[part 1 of 2: packages /AUTOSAR_Platform/DataConstrs to /PATAC/MSM/DataTypes/ImplementationDataTypes]
AUTOSAR XML (schema 4-0-3)
standard types defined: Boolean, UInt16, UInt32, UInt8
package /AUTOSAR_Platform/DataConstrs
  range DC_Boolean: raw 0..1
  range DC_UInt16: raw 0..65535
  range DC_UInt8: raw 0..255
package /PATAC/Facility/DataTypes/Implementation
  unit NoUnit: factor-si-to-unit=1, offset-si-to-unit=0
package /PATAC/MSM/ComponentTypes
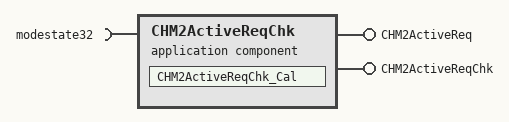
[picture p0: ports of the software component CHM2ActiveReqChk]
  application sw component type CHM2ActiveReqChk
    provide port CHM2ActiveReq: nonqueued-sender-com-spec{data-element=CHM2ActiveReq/Val, init-value=0}, provided-interface=CHM2ActiveReq
    provide port CHM2ActiveReqChk: server-com-spec{operation=CHM2ActiveReqChk/Cal, queue-length=1}, provided-interface=CHM2ActiveReqChk
    require port modestate32: nonqueued-receiver-com-spec{data-element=modestate32/Val, filter=data-filter-type=ALWAYS, init-value=0}, required-interface=modestate32
    behavior CHM2ActiveReqChk_InternalBehavior
      operation invoked event OIT_CHM2ActiveReqChk_Cal_CHM2ActiveReqChk_Cal: start-on-event=CHM2ActiveReqChk_Cal, operation=CHM2ActiveReqChk.Cal
      runnable CHM2ActiveReqChk_Cal
        data-receive-point-by-arguments:
          access REC_modestate32_Val: accessed-variable=modestate32.Val
        data-send-points:
          access SEND_CHM2ActiveReq_Val: accessed-variable=CHM2ActiveReq.Val
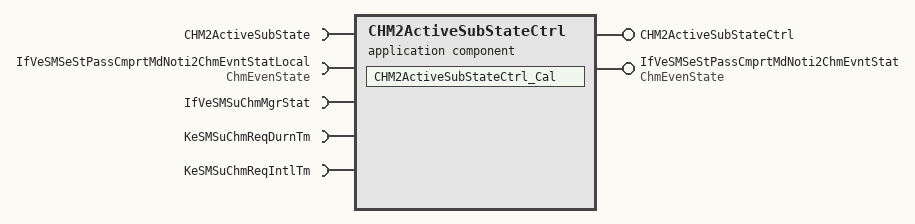
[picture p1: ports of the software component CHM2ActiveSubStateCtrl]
  application sw component type CHM2ActiveSubStateCtrl
    provide port CHM2ActiveSubStateCtrl: server-com-spec{operation=CHM2ActiveSubStateCtrl/Cal, queue-length=1}, provided-interface=CHM2ActiveSubStateCtrl
    provide port IfVeSMSeStPassCmprtMdNoti2ChmEvntStat: nonqueued-sender-com-spec{data-element=ChmEvenState/Val, init-value=0}, provided-interface=ChmEvenState
    5 x require port:
      CHM2ActiveSubState: nonqueued-receiver-com-spec{data-element=CHM2ActiveSubState/Val, filter=data-filter-type=ALWAYS, init-value=0}, required-interface=CHM2ActiveSubState
      IfVeSMSeStPassCmprtMdNoti2ChmEvntStatLocal: nonqueued-receiver-com-spec{data-element=ChmEvenState/Val, filter=data-filter-type=ALWAYS, init-value=0}, required-interface=ChmEvenState
      IfVeSMSuChmMgrStat: nonqueued-receiver-com-spec{data-element=IfVeSMSuChmMgrStat/Val, filter=data-filter-type=ALWAYS, init-value=0}, required-interface=IfVeSMSuChmMgrStat
      KeSMSuChmReqDurnTm: parameter-require-com-spec{init-value=200, parameter=KeSMSuChmReqDurnTm/Val}, required-interface=KeSMSuChmReqDurnTm
      KeSMSuChmReqIntlTm: parameter-require-com-spec{init-value=50, parameter=KeSMSuChmReqIntlTm/Val}, required-interface=KeSMSuChmReqIntlTm
    behavior CHM2ActiveSubStateCtrl_InternalBehavior
      operation invoked event OIT_CHM2ActiveSubStateCtrl_Cal_CHM2ActiveSubStateCtrl_Cal: start-on-event=CHM2ActiveSubStateCtrl_Cal, operation=CHM2ActiveSubStateCtrl.Cal
      runnable CHM2ActiveSubStateCtrl_Cal
        data-receive-point-by-arguments:
          access REC_CHM2ActiveSubState_Val: accessed-variable=CHM2ActiveSubState.Val
          access REC_IfVeSMSeStPassCmprtMdNoti2ChmEvntStatLocal_Val: accessed-variable=IfVeSMSeStPassCmprtMdNoti2ChmEvntStatLocal.Val
          access REC_IfVeSMSuChmMgrStat_Val: accessed-variable=IfVeSMSuChmMgrStat.Val
        data-send-points:
          access SEND_IfVeSMSeStPassCmprtMdNoti2ChmEvntStat_Val: accessed-variable=IfVeSMSeStPassCmprtMdNoti2ChmEvntStat.Val
        parameter access PA_KeSMSuChmReqDurnTm_Val: accessed-parameter=KeSMSuChmReqDurnTm.Val
        parameter access PA_KeSMSuChmReqIntlTm_Val: accessed-parameter=KeSMSuChmReqIntlTm.Val
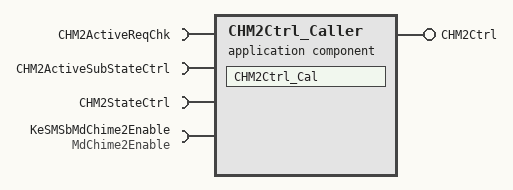
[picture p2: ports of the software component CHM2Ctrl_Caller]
  application sw component type CHM2Ctrl_Caller
    provide port CHM2Ctrl: server-com-spec{operation=CHM2Ctrl/Cal, queue-length=1}, provided-interface=CHM2Ctrl
    4 x require port:
      CHM2ActiveReqChk: client-com-spec=CHM2ActiveReqChk/Cal, required-interface=CHM2ActiveReqChk
      CHM2ActiveSubStateCtrl: client-com-spec=CHM2ActiveSubStateCtrl/Cal, required-interface=CHM2ActiveSubStateCtrl
      CHM2StateCtrl: client-com-spec=CHM2StateCtrl/Cal, required-interface=CHM2StateCtrl
      KeSMSbMdChime2Enable: parameter-require-com-spec{init-value=0, parameter=MdChime2Enable/Val}, required-interface=MdChime2Enable
    behavior CHM2Ctrl_Caller_InternalBehavior
      operation invoked event OIT_CHM2Ctrl_Cal_CHM2Ctrl_Cal: start-on-event=CHM2Ctrl_Cal, operation=CHM2Ctrl.Cal
      runnable CHM2Ctrl_Cal
        parameter access PA_KeSMSbMdChime2Enable_Val: accessed-parameter=KeSMSbMdChime2Enable.Val
        sync call SC_CHM2ActiveReqChk_Cal: operation=CHM2ActiveReqChk.Cal, timeout=0
        sync call SC_CHM2ActiveSubStateCtrl_Cal: operation=CHM2ActiveSubStateCtrl.Cal, timeout=0
        sync call SC_CHM2StateCtrl_Cal: operation=CHM2StateCtrl.Cal, timeout=0
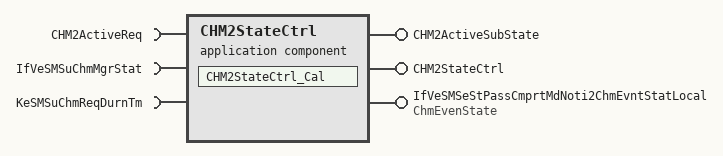
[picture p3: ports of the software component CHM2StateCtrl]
  application sw component type CHM2StateCtrl
    provide port CHM2ActiveSubState: nonqueued-sender-com-spec{data-element=CHM2ActiveSubState/Val, init-value=0}, provided-interface=CHM2ActiveSubState
    provide port CHM2StateCtrl: server-com-spec{operation=CHM2StateCtrl/Cal, queue-length=1}, provided-interface=CHM2StateCtrl
    provide port IfVeSMSeStPassCmprtMdNoti2ChmEvntStatLocal: nonqueued-sender-com-spec{data-element=ChmEvenState/Val, init-value=0}, provided-interface=ChmEvenState
    require port CHM2ActiveReq: nonqueued-receiver-com-spec{data-element=CHM2ActiveReq/Val, filter=data-filter-type=ALWAYS, init-value=0}, required-interface=CHM2ActiveReq
    require port IfVeSMSuChmMgrStat: nonqueued-receiver-com-spec{data-element=IfVeSMSuChmMgrStat/Val, filter=data-filter-type=ALWAYS, init-value=0}, required-interface=IfVeSMSuChmMgrStat
    require port KeSMSuChmReqDurnTm: parameter-require-com-spec{init-value=200, parameter=KeSMSuChmReqDurnTm/Val}, required-interface=KeSMSuChmReqDurnTm
    behavior CHM2StateCtrl_InternalBehavior
      operation invoked event OIT_CHM2StateCtrl_Cal_CHM2StateCtrl_Cal: start-on-event=CHM2StateCtrl_Cal, operation=CHM2StateCtrl.Cal
      runnable CHM2StateCtrl_Cal
        data-receive-point-by-arguments:
          access REC_CHM2ActiveReq_Val: accessed-variable=CHM2ActiveReq.Val
          access REC_IfVeSMSuChmMgrStat_Val: accessed-variable=IfVeSMSuChmMgrStat.Val
        data-send-points:
          access SEND_CHM2ActiveSubState_Val: accessed-variable=CHM2ActiveSubState.Val
          access SEND_IfVeSMSeStPassCmprtMdNoti2ChmEvntStatLocal_Val: accessed-variable=IfVeSMSeStPassCmprtMdNoti2ChmEvntStatLocal.Val
        parameter access PA_KeSMSuChmReqDurnTm_Val: accessed-parameter=KeSMSuChmReqDurnTm.Val
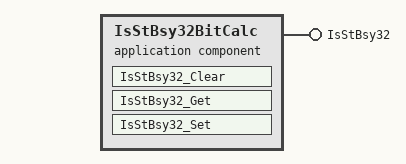
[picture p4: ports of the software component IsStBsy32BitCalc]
  application sw component type IsStBsy32BitCalc
    provide port IsStBsy32: provided-interface=IsStBsy32
      provided-com-specs:
        operation=IsStBsy32/Clear, queue-length=1
        operation=IsStBsy32/Get, queue-length=1
        operation=IsStBsy32/Set, queue-length=1
    behavior IsStBsy32BitCalc_InternalBehavior
      operation invoked event OIT_IsStBsy32_Clear_IsStBsy32_Clear: start-on-event=IsStBsy32_Clear, operation=IsStBsy32.Clear
      operation invoked event OIT_IsStBsy32_Get_IsStBsy32_Get: start-on-event=IsStBsy32_Get, operation=IsStBsy32.Get
      operation invoked event OIT_IsStBsy32_Set_IsStBsy32_Set: start-on-event=IsStBsy32_Set, operation=IsStBsy32.Set
      runnable IsStBsy32_Clear
      runnable IsStBsy32_Get
      runnable IsStBsy32_Set
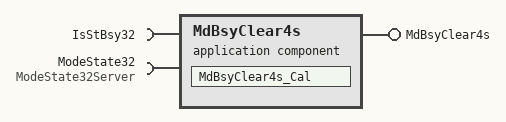
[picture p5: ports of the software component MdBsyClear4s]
  application sw component type MdBsyClear4s
    provide port MdBsyClear4s: server-com-spec{operation=MdBsyClear4s/Cal, queue-length=1}, provided-interface=MdBsyClear4s
    require port IsStBsy32: required-com-specs=[IsStBsy32/Clear, IsStBsy32/Get, IsStBsy32/Set], required-interface=IsStBsy32
    require port ModeState32: required-com-specs=[ModeState32Server/Clear, ModeState32Server/Get, ModeState32Server/Set], required-interface=ModeState32Server
    behavior MdBsyClear4s_InternalBehavior
      operation invoked event OIT_MdBsyClear4s_Cal_MdBsyClear4s_Cal: start-on-event=MdBsyClear4s_Cal, operation=MdBsyClear4s.Cal
      runnable MdBsyClear4s_Cal
        sync call SC_IsStBsy32_Clear: operation=IsStBsy32.Clear, timeout=0
        sync call SC_ModeState32_Get: operation=ModeState32.Get, timeout=0
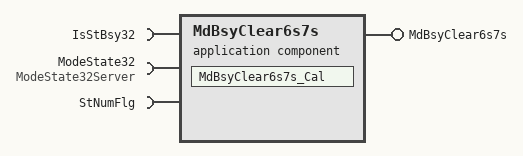
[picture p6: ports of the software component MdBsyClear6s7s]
  application sw component type MdBsyClear6s7s
    provide port MdBsyClear6s7s: server-com-spec{operation=MdBsyClear6s7s/Cal, queue-length=1}, provided-interface=MdBsyClear6s7s
    require port IsStBsy32: required-com-specs=[IsStBsy32/Clear, IsStBsy32/Get, IsStBsy32/Set], required-interface=IsStBsy32
    require port ModeState32: required-com-specs=[ModeState32Server/Clear, ModeState32Server/Get, ModeState32Server/Set], required-interface=ModeState32Server
    require port StNumFlg: required-interface=StNumFlg
      required-com-specs:
        data-element=Is4s, filter=data-filter-type=ALWAYS, init-value=0
        data-element=Is6s, filter=data-filter-type=ALWAYS, init-value=0
        data-element=Is6s7s, filter=data-filter-type=ALWAYS, init-value=0
        data-element=Is7s, filter=data-filter-type=ALWAYS, init-value=0
    behavior MdBsyClear6s7s_InternalBehavior
      operation invoked event OIT_MdBsyClear6s7s_Cal_MdBsyClear6s7s_Cal: start-on-event=MdBsyClear6s7s_Cal, operation=MdBsyClear6s7s.Cal
      runnable MdBsyClear6s7s_Cal
        data-receive-point-by-arguments:
          access REC_StNumFlg_Is6s: accessed-variable=StNumFlg.Is6s
          access REC_StNumFlg_Is7s: accessed-variable=StNumFlg.Is7s
        sync call SC_IsStBsy32_Clear: operation=IsStBsy32.Clear, timeout=0
        sync call SC_ModeState32_Get: operation=ModeState32.Get, timeout=0
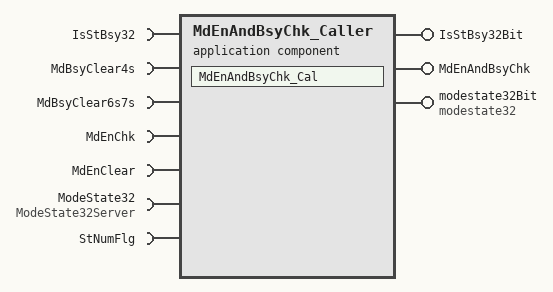
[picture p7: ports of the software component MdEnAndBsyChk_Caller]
  application sw component type MdEnAndBsyChk_Caller
    provide port IsStBsy32Bit: nonqueued-sender-com-spec{data-element=IsStBsy32Bit/Val, init-value=0}, provided-interface=IsStBsy32Bit
    provide port MdEnAndBsyChk: server-com-spec{operation=MdEnAndBsyChk/Cal, queue-length=1}, provided-interface=MdEnAndBsyChk
    provide port modestate32Bit: nonqueued-sender-com-spec{data-element=modestate32/Val, init-value=0}, provided-interface=modestate32
    7 x require port:
      IsStBsy32: required-com-specs=[IsStBsy32/Clear, IsStBsy32/Get, IsStBsy32/Set], required-interface=IsStBsy32
      MdBsyClear4s: client-com-spec=MdBsyClear4s/Cal, required-interface=MdBsyClear4s
      MdBsyClear6s7s: client-com-spec=MdBsyClear6s7s/Cal, required-interface=MdBsyClear6s7s
      MdEnChk: client-com-spec=MdEnChk/Cal, required-interface=MdEnChk
      MdEnClear: client-com-spec=MdEnClear/Cal, required-interface=MdEnClear
      ModeState32: required-com-specs=[ModeState32Server/Clear, ModeState32Server/Get, ModeState32Server/Set], required-interface=ModeState32Server
      StNumFlg: required-interface=StNumFlg
        required-com-specs:
          data-element=Is4s, filter=data-filter-type=ALWAYS, init-value=0
          data-element=Is6s, filter=data-filter-type=ALWAYS, init-value=0
          data-element=Is6s7s, filter=data-filter-type=ALWAYS, init-value=0
          data-element=Is7s, filter=data-filter-type=ALWAYS, init-value=0
    behavior MdEnAndBsyChk_Caller_InternalBehavior
      operation invoked event OIT_MdEnAndBsyChk_Cal_MdEnAndBsyChk_Cal: start-on-event=MdEnAndBsyChk_Cal, operation=MdEnAndBsyChk.Cal
      runnable MdEnAndBsyChk_Cal
        data-receive-point-by-arguments:
          4 x access:
            REC_StNumFlg_Is4s: accessed-variable=StNumFlg.Is4s
            REC_StNumFlg_Is6s: accessed-variable=StNumFlg.Is6s
            REC_StNumFlg_Is6s7s: accessed-variable=StNumFlg.Is6s7s
            REC_StNumFlg_Is7s: accessed-variable=StNumFlg.Is7s
        data-send-points:
          access SEND_IsStBsy32Bit_Val: accessed-variable=IsStBsy32Bit.Val
          access SEND_modestate32_Val: accessed-variable=modestate32Bit.Val
        6 x sync call, all with timeout=0:
          SC_IsStBsy32_Get: operation=IsStBsy32.Get
          SC_MdBsyClear4s_Cal: operation=MdBsyClear4s.Cal
          SC_MdBsyClear6s7s_Cal: operation=MdBsyClear6s7s.Cal
          SC_MdEnChk_Cal: operation=MdEnChk.Cal
          SC_MdEnClear_Cal: operation=MdEnClear.Cal
          SC_ModeState32_Get: operation=ModeState32.Get
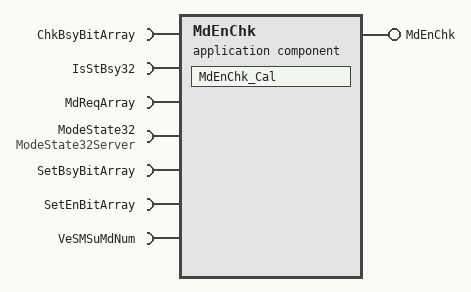
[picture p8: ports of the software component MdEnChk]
  application sw component type MdEnChk
    provide port MdEnChk: server-com-spec{operation=MdEnChk/Cal, queue-length=1}, provided-interface=MdEnChk
    7 x require port:
      ChkBsyBitArray: nonqueued-receiver-com-spec{data-element=ChkBsyBitArray/Val, filter=data-filter-type=ALWAYS, init-value=32 x 0}, required-interface=ChkBsyBitArray
      IsStBsy32: required-com-specs=[IsStBsy32/Clear, IsStBsy32/Get, IsStBsy32/Set], required-interface=IsStBsy32
      MdReqArray: nonqueued-receiver-com-spec{data-element=MdReqArray/Val, filter=data-filter-type=ALWAYS, init-value=32 x 0}, required-interface=MdReqArray
      ModeState32: required-com-specs=[ModeState32Server/Clear, ModeState32Server/Get, ModeState32Server/Set], required-interface=ModeState32Server
      SetBsyBitArray: nonqueued-receiver-com-spec{data-element=SetBsyBitArray/Val, filter=data-filter-type=ALWAYS, init-value=32 x 0}, required-interface=SetBsyBitArray
      SetEnBitArray: nonqueued-receiver-com-spec{data-element=SetEnBitArray/Val, filter=data-filter-type=ALWAYS, init-value=32 x 0}, required-interface=SetEnBitArray
      VeSMSuMdNum: nonqueued-receiver-com-spec{data-element=VeSMSuMdNum/Val, filter=data-filter-type=ALWAYS, init-value=0}, required-interface=VeSMSuMdNum
    behavior MdEnChk_InternalBehavior
      operation invoked event OIT_MdEnChk_Cal_MdEnChk_Cal: start-on-event=MdEnChk_Cal, operation=MdEnChk.Cal
      runnable MdEnChk_Cal
        data-receive-point-by-arguments:
          5 x access:
            REC_ChkBsyBitArray_Val: accessed-variable=ChkBsyBitArray.Val
            REC_MdReqArray_Val: accessed-variable=MdReqArray.Val
            REC_SetBsyBitArray_Val: accessed-variable=SetBsyBitArray.Val
            REC_SetEnBitArray_Val: accessed-variable=SetEnBitArray.Val
            REC_VeSMSuMdNum_Val: accessed-variable=VeSMSuMdNum.Val
        sync call SC_IsStBsy32_Get: operation=IsStBsy32.Get, timeout=0
        sync call SC_IsStBsy32_Set: operation=IsStBsy32.Set, timeout=0
        sync call SC_ModeState32_Set: operation=ModeState32.Set, timeout=0
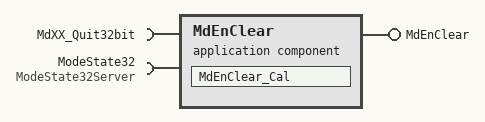
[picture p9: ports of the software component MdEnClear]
  application sw component type MdEnClear
    provide port MdEnClear: server-com-spec{operation=MdEnClear/Cal, queue-length=1}, provided-interface=MdEnClear
    require port MdXX_Quit32bit: nonqueued-receiver-com-spec{data-element=MdXX_Quit32bit/Val, filter=data-filter-type=ALWAYS, init-value=0}, required-interface=MdXX_Quit32bit
    require port ModeState32: required-com-specs=[ModeState32Server/Clear, ModeState32Server/Get, ModeState32Server/Set], required-interface=ModeState32Server
    behavior MdEnClear_InternalBehavior
      operation invoked event OIT_MdEnClear_Cal_MdEnClear_Cal: start-on-event=MdEnClear_Cal, operation=MdEnClear.Cal
      runnable MdEnClear_Cal
        data-receive-point-by-arguments:
          access REC_MdXX_Quit32bit_Val: accessed-variable=MdXX_Quit32bit.Val
        sync call SC_ModeState32_Clear: operation=ModeState32.Clear, timeout=0
        sync call SC_ModeState32_Get: operation=ModeState32.Get, timeout=0
  application sw component type MdSWReqChk
    6 x provide port:
      ChkBsyBitArray: nonqueued-sender-com-spec=data-element=ChkBsyBitArray/Val, provided-interface=ChkBsyBitArray
      MdReqArray: nonqueued-sender-com-spec=data-element=MdReqArray/Val, provided-interface=MdReqArray
      MdSWReqChk: server-com-spec{operation=MdSWReqChk/Cal, queue-length=1}, provided-interface=MdSWReqChk
      SetBsyBitArray: nonqueued-sender-com-spec=data-element=SetBsyBitArray/Val, provided-interface=SetBsyBitArray
      SetEnBitArray: nonqueued-sender-com-spec=data-element=SetEnBitArray/Val, provided-interface=SetEnBitArray
      VeSMSuMdNum: nonqueued-sender-com-spec=data-element=VeSMSuMdNum/Val, provided-interface=VeSMSuMdNum
    45 x require port:
      acsEntyMdReq: nonqueued-receiver-com-spec{data-element=MdReq/Val, filter=data-filter-type=ALWAYS, init-value=0}, required-interface=MdReq
      acsExtMdReq: nonqueued-receiver-com-spec{data-element=MdReq/Val, filter=data-filter-type=ALWAYS, init-value=0}, required-interface=MdReq
      AllLugMdReq: nonqueued-receiver-com-spec{data-element=MdReq/Val, filter=data-filter-type=ALWAYS, init-value=0}, required-interface=MdReq
      AllVipMdReq: nonqueued-receiver-com-spec{data-element=MdReq/Val, filter=data-filter-type=ALWAYS, init-value=0}, required-interface=MdReq
      EZE4sLtMdReq: nonqueued-receiver-com-spec{data-element=AnyModeAjust/Val, filter=data-filter-type=ALWAYS, init-value=0}, required-interface=AnyModeAjust
      EZE4sRtMdReq: nonqueued-receiver-com-spec{data-element=AnyModeAjust/Val, filter=data-filter-type=ALWAYS, init-value=0}, required-interface=AnyModeAjust
      EZQ4sLtMdReq: nonqueued-receiver-com-spec{data-element=AnyModeAjust/Val, filter=data-filter-type=ALWAYS, init-value=0}, required-interface=AnyModeAjust
      EZQ4sRtMdReq: nonqueued-receiver-com-spec{data-element=AnyModeAjust/Val, filter=data-filter-type=ALWAYS, init-value=0}, required-interface=AnyModeAjust
      IfVeSMSuSecRwLtStFrwdBkwdPos: nonqueued-receiver-com-spec{data-element=IfVeSMSuSecRwLtStFrwdBkwdPos/Val, filter=data-filter-type=ALWAYS, init-value=0}, required-interface=IfVeSMSuSecRwLtStFrwdBkwdPos
      IfVeSMSuSecRwRtStFrwdBkwdPos: nonqueued-receiver-com-spec{data-element=PercPos/Val, filter=data-filter-type=ALWAYS, init-value=0}, required-interface=PercPos
      IntimacyRtMdReq: nonqueued-receiver-com-spec{data-element=AnyModeAjust/Val, filter=data-filter-type=ALWAYS, init-value=0}, required-interface=AnyModeAjust
      INTMMdReq: nonqueued-receiver-com-spec{data-element=MdReq/Val, filter=data-filter-type=ALWAYS, init-value=0}, required-interface=MdReq
      KeSMSAutoEZEFwdBkwdPosEna: parameter-require-com-spec{init-value=0, parameter=KeSMSAutoEZEFwdBkwdPosEna/Val}, required-interface=KeSMSAutoEZEFwdBkwdPosEna
      KeSMSuButtonLongPressedThrshldTm: parameter-require-com-spec{init-value=100, parameter=KeSMSuButtonLongPressedThrshldTm/Val}, required-interface=KeSMSuButtonLongPressedThrshldTm
      KeSMSuMdNum4s: parameter-require-com-spec{init-value=16, parameter=KeSMSuMdNum4s/Val}, required-interface=KeSMSuMdNum4s
      KeSMSuMdNum6s7s: parameter-require-com-spec{init-value=14, parameter=KeSMSuMdNum6s7s/Val}, required-interface=KeSMSuMdNum6s7s
      LfFamlyReq: nonqueued-receiver-com-spec{data-element=MdReq/Val, filter=data-filter-type=ALWAYS, init-value=0}, required-interface=MdReq
      LfLyMdReq: nonqueued-receiver-com-spec{data-element=MdReq/Val, filter=data-filter-type=ALWAYS, init-value=0}, required-interface=MdReq
      LgrstCloseLtMdReq: nonqueued-receiver-com-spec{data-element=AnyModeAjust/Val, filter=data-filter-type=ALWAYS, init-value=0}, required-interface=AnyModeAjust
      LgrstCloseRtMdReq: nonqueued-receiver-com-spec{data-element=AnyModeAjust/Val, filter=data-filter-type=ALWAYS, init-value=0}, required-interface=AnyModeAjust
      LgrstOpenLtMdReq: nonqueued-receiver-com-spec{data-element=AnyModeAjust/Val, filter=data-filter-type=ALWAYS, init-value=0}, required-interface=AnyModeAjust
      LgrstOpenRtMdReq: nonqueued-receiver-com-spec{data-element=AnyModeAjust/Val, filter=data-filter-type=ALWAYS, init-value=0}, required-interface=AnyModeAjust
      LtLugMdReq: nonqueued-receiver-com-spec{data-element=MdReq/Val, filter=data-filter-type=ALWAYS, init-value=0}, required-interface=MdReq
      LtRcvyMdReq: nonqueued-receiver-com-spec{data-element=MdReq/Val, filter=data-filter-type=ALWAYS, init-value=0}, required-interface=MdReq
      LtVipMdReq: nonqueued-receiver-com-spec{data-element=MdReq/Val, filter=data-filter-type=ALWAYS, init-value=0}, required-interface=MdReq
      LugMdLtAvl: nonqueued-receiver-com-spec{data-element=ModeAdjustAvailable/Val, filter=data-filter-type=ALWAYS, init-value=0}, required-interface=ModeAdjustAvailable
      LugMdRtAvl: nonqueued-receiver-com-spec{data-element=ModeAdjustAvailable/Val, filter=data-filter-type=ALWAYS, init-value=0}, required-interface=ModeAdjustAvailable
      MdSWIntSrc_R: nonqueued-receiver-com-spec{data-element=MdSWIntSrc_R/Val, filter=data-filter-type=ALWAYS, init-value=0}, required-interface=MdSWIntSrc_R
      RtFamlyMdReq: nonqueued-receiver-com-spec{data-element=MdReq/Val, filter=data-filter-type=ALWAYS, init-value=0}, required-interface=MdReq
      RtLugMdReq: nonqueued-receiver-com-spec{data-element=MdReq/Val, filter=data-filter-type=ALWAYS, init-value=0}, required-interface=MdReq
      RtLyMdReq: nonqueued-receiver-com-spec{data-element=MdReq/Val, filter=data-filter-type=ALWAYS, init-value=0}, required-interface=MdReq
      RtRcvyMdReq: nonqueued-receiver-com-spec{data-element=MdReq/Val, filter=data-filter-type=ALWAYS, init-value=0}, required-interface=MdReq
      RtVipMdReq: nonqueued-receiver-com-spec{data-element=MdReq/Val, filter=data-filter-type=ALWAYS, init-value=0}, required-interface=MdReq
      StNumFlg: required-interface=StNumFlg
        required-com-specs:
          data-element=Is4s, filter=data-filter-type=ALWAYS, init-value=0
          data-element=Is6s, filter=data-filter-type=ALWAYS, init-value=0
          data-element=Is6s7s, filter=data-filter-type=ALWAYS, init-value=0
          data-element=Is7s, filter=data-filter-type=ALWAYS, init-value=0
      SwIntAcsEnty: nonqueued-receiver-com-spec{data-element=IntEnable/Val, filter=data-filter-type=ALWAYS, init-value=0}, required-interface=IntEnable
      SwIntAcsExt: nonqueued-receiver-com-spec{data-element=IntEnable/Val, filter=data-filter-type=ALWAYS, init-value=0}, required-interface=IntEnable
      SwIntAllLug: nonqueued-receiver-com-spec{data-element=IntEnable/Val, filter=data-filter-type=ALWAYS, init-value=0}, required-interface=IntEnable
      SwIntLfRcvy: nonqueued-receiver-com-spec{data-element=IntEnable/Val, filter=data-filter-type=ALWAYS, init-value=0}, required-interface=IntEnable
      SwIntLfVip: nonqueued-receiver-com-spec{data-element=IntEnable/Val, filter=data-filter-type=ALWAYS, init-value=0}, required-interface=IntEnable
      SwIntRtRcvy: nonqueued-receiver-com-spec{data-element=IntEnable/Val, filter=data-filter-type=ALWAYS, init-value=0}, required-interface=IntEnable
      SwIntRtVip: nonqueued-receiver-com-spec{data-element=IntEnable/Val, filter=data-filter-type=ALWAYS, init-value=0}, required-interface=IntEnable
      VipMdLtAvl: nonqueued-receiver-com-spec{data-element=ModeAdjustAvailable/Val, filter=data-filter-type=ALWAYS, init-value=0}, required-interface=ModeAdjustAvailable
      VipMdRtAvl: nonqueued-receiver-com-spec{data-element=ModeAdjustAvailable/Val, filter=data-filter-type=ALWAYS, init-value=0}, required-interface=ModeAdjustAvailable
      WelcomeBkwdMdReq: nonqueued-receiver-com-spec{data-element=AnyModeAjust/Val, filter=data-filter-type=ALWAYS, init-value=0}, required-interface=AnyModeAjust
      WelcomeFwdMdReq: nonqueued-receiver-com-spec{data-element=AnyModeAjust/Val, filter=data-filter-type=ALWAYS, init-value=0}, required-interface=AnyModeAjust
    behavior MdSWReqChk_InternalBehavior
      operation invoked event OIT_MdSWReqChk_Cal_MdSWReqChk_Cal: start-on-event=MdSWReqChk_Cal, operation=MdSWReqChk.Cal
      runnable MdSWReqChk_Cal
        data-receive-point-by-arguments:
          44 x access:
            REC_acsEntyMdReq_Val: accessed-variable=acsEntyMdReq.Val
            REC_acsExtMdReq_Val: accessed-variable=acsExtMdReq.Val
            REC_AllLugMdReq_Val: accessed-variable=AllLugMdReq.Val
            REC_AllVipMdReq_Val: accessed-variable=AllVipMdReq.Val
            REC_EZE4sLtMdReq_Val: accessed-variable=EZE4sLtMdReq.Val
            REC_EZE4sRtMdReq_Val: accessed-variable=EZE4sRtMdReq.Val
            REC_EZQ4sLtMdReq_Val: accessed-variable=EZQ4sLtMdReq.Val
            REC_EZQ4sRtMdReq_Val: accessed-variable=EZQ4sRtMdReq.Val
            REC_IfVeSMSuSecRwLtStFrwdBkwdPos_Val: accessed-variable=IfVeSMSuSecRwLtStFrwdBkwdPos.Val
            REC_IfVeSMSuSecRwRtStFrwdBkwdPos_Val: accessed-variable=IfVeSMSuSecRwRtStFrwdBkwdPos.Val
            REC_IntimacyRtMdReq_Val: accessed-variable=IntimacyRtMdReq.Val
            REC_INTMMdReq_Val: accessed-variable=INTMMdReq.Val
            REC_LfFamlyReq_Val: accessed-variable=LfFamlyReq.Val
            REC_LfLyMdReq_Val: accessed-variable=LfLyMdReq.Val
            REC_LgrstCloseLtMdReq_Val: accessed-variable=LgrstCloseLtMdReq.Val
            REC_LgrstCloseRtMdReq_Val: accessed-variable=LgrstCloseRtMdReq.Val
            REC_LgrstOpenLtMdReq_Val: accessed-variable=LgrstOpenLtMdReq.Val
            REC_LgrstOpenRtMdReq_Val: accessed-variable=LgrstOpenRtMdReq.Val
            REC_LtLugMdReq_Val: accessed-variable=LtLugMdReq.Val
            REC_LtRcvyMdReq_Val: accessed-variable=LtRcvyMdReq.Val
            REC_LtVipMdReq_Val: accessed-variable=LtVipMdReq.Val
            REC_LugMdLtAvl_Val: accessed-variable=LugMdLtAvl.Val
            REC_LugMdRtAvl_Val: accessed-variable=LugMdRtAvl.Val
            REC_MdSWIntSrc_R_Val: accessed-variable=MdSWIntSrc_R.Val
            REC_RtFamlyMdReq_Val: accessed-variable=RtFamlyMdReq.Val
            REC_RtLugMdReq_Val: accessed-variable=RtLugMdReq.Val
            REC_RtLyMdReq_Val: accessed-variable=RtLyMdReq.Val
            REC_RtRcvyMdReq_Val: accessed-variable=RtRcvyMdReq.Val
            REC_RtVipMdReq_Val: accessed-variable=RtVipMdReq.Val
            REC_StNumFlg_Is4s: accessed-variable=StNumFlg.Is4s
            REC_StNumFlg_Is6s: accessed-variable=StNumFlg.Is6s
            REC_StNumFlg_Is6s7s: accessed-variable=StNumFlg.Is6s7s
            REC_StNumFlg_Is7s: accessed-variable=StNumFlg.Is7s
            REC_SwIntAcsEnty_Val: accessed-variable=SwIntAcsEnty.Val
            REC_SwIntAcsExt_Val: accessed-variable=SwIntAcsExt.Val
            REC_SwIntAllLug_Val: accessed-variable=SwIntAllLug.Val
            REC_SwIntLfRcvy_Val: accessed-variable=SwIntLfRcvy.Val
            REC_SwIntLfVip_Val: accessed-variable=SwIntLfVip.Val
            REC_SwIntRtRcvy_Val: accessed-variable=SwIntRtRcvy.Val
            REC_SwIntRtVip_Val: accessed-variable=SwIntRtVip.Val
            REC_VipMdLtAvl_Val: accessed-variable=VipMdLtAvl.Val
            REC_VipMdRtAvl_Val: accessed-variable=VipMdRtAvl.Val
            REC_WelcomeBkwdMdReq_Val: accessed-variable=WelcomeBkwdMdReq.Val
            REC_WelcomeFwdMdReq_Val: accessed-variable=WelcomeFwdMdReq.Val
        data-send-points:
          5 x access:
            SEND_ChkBsyBitArray_Val: accessed-variable=ChkBsyBitArray.Val
            SEND_MdReqArray_Val: accessed-variable=MdReqArray.Val
            SEND_SetBsyBitArray_Val: accessed-variable=SetBsyBitArray.Val
            SEND_SetEnBitArray_Val: accessed-variable=SetEnBitArray.Val
            SEND_VeSMSuMdNum_Val: accessed-variable=VeSMSuMdNum.Val
        4 x parameter access:
          PA_KeSMSAutoEZEFwdBkwdPosEna_Val: accessed-parameter=KeSMSAutoEZEFwdBkwdPosEna.Val
          PA_KeSMSuButtonLongPressedThrshldTm_Val: accessed-parameter=KeSMSuButtonLongPressedThrshldTm.Val
          PA_KeSMSuMdNum4s_Val: accessed-parameter=KeSMSuMdNum4s.Val
          PA_KeSMSuMdNum6s7s_Val: accessed-parameter=KeSMSuMdNum6s7s.Val
  application sw component type MdXX_QuitChk
    provide port MdXX_Quit32bit: nonqueued-sender-com-spec{data-element=MdXX_Quit32bit/Val, init-value=0}, provided-interface=MdXX_Quit32bit
    provide port MdXX_QuitArray: nonqueued-sender-com-spec{data-element=MdXX_QuitArray/Val, init-value=32 x 0}, provided-interface=MdXX_QuitArray
    provide port MdXX_QuitChk: server-com-spec{operation=MdXX_QuitChk/Cal, queue-length=1}, provided-interface=MdXX_QuitChk
    6 x require port:
      KeSMSuMdNums: parameter-require-com-spec{init-value=26, parameter=KeSMSuMdNums/Val}, required-interface=KeSMSuMdNums
      MdXX_CommExitArray: nonqueued-receiver-com-spec{data-element=MdXX_CommExitArray/Val, filter=data-filter-type=ALWAYS, init-value=32 x 0}, required-interface=MdXX_CommExitArray
      MdXX_MdDoneArray: nonqueued-receiver-com-spec{data-element=MdXX_MdDoneArray/Val, filter=data-filter-type=ALWAYS, init-value=32 x 0}, required-interface=MdXX_MdDoneArray
      MdXX_QuitReason: client-com-spec=Calc, required-interface=MdXX_QuitReason
      MdXX_SoftIntArray: nonqueued-receiver-com-spec{data-element=MdXX_SoftIntArray/Val, filter=data-filter-type=ALWAYS, init-value=32 x 0}, required-interface=MdXX_SoftIntArray
      MdXX_SWIntArray: nonqueued-receiver-com-spec{data-element=MdXX_SWIntArray/Val, filter=data-filter-type=ALWAYS, init-value=32 x 0}, required-interface=MdXX_SWIntArray
    behavior MdXX_QuitChk_InternalBehavior
      operation invoked event OIT_MdXX_QuitChk_Cal_MdXX_QuitChk_Cal: start-on-event=MdXX_QuitChk_Cal, operation=MdXX_QuitChk.Cal
      runnable MdXX_QuitChk_Cal
        data-receive-point-by-arguments:
          4 x access:
            SEND_MdXX_CommExitArray_Val: accessed-variable=MdXX_CommExitArray.Val
            SEND_MdXX_MdDoneArray_Val: accessed-variable=MdXX_MdDoneArray.Val
            SEND_MdXX_SoftIntArray_Val: accessed-variable=MdXX_SoftIntArray.Val
            SEND_MdXX_SWIntArray_Val: accessed-variable=MdXX_SWIntArray.Val
        data-send-points:
          access SEND_MdXX_Quit32bit_Val: accessed-variable=MdXX_Quit32bit.Val
          access SEND_MdXX_QuitArray_Val: accessed-variable=MdXX_QuitArray.Val
        parameter access PA_KeSMSuMdNums_Val: accessed-parameter=KeSMSuMdNums.Val
        sync call SC_MdXX_QuitReason_Calc: operation=MdXX_QuitReason.Calc, timeout=0
  application sw component type MdXX_QuitReason
    provide port MdXX_QuitReason: server-com-spec{operation=Calc, queue-length=1}, provided-interface=MdXX_QuitReason
    behavior MdXX_QuitReason_InternalBehavior
      operation invoked event OIT_MdXX_QuitReason_Calc_MdXX_QuitReason_Calc: start-on-event=MdXX_QuitReason_Calc, operation=MdXX_QuitReason.Calc
      runnable MdXX_QuitReason_Calc
  application sw component type MdXX_RspOutComm
    provide port MdXX_RspOutComm: provided-interface=MdXX_RspOutComm
      provided-com-specs:
        data-element=Md1_RspOutComm, init-value=0
        data-element=Md{10..19}_RspOutComm, init-value=0
        data-element=Md2_RspOutComm, init-value=0
        data-element=Md{20..29}_RspOutComm, init-value=0
        data-element=Md3_RspOutComm, init-value=0
        data-element=Md{30..32}_RspOutComm, init-value=0
        data-element=Md{4..9}_RspOutComm, init-value=0
    provide port MdXX_RspOutCommCalc: server-com-spec{operation=MdXX_RspOutCommCalc/Cal, queue-length=1}, provided-interface=MdXX_RspOutCommCalc
    provide port MdXX_SrcReqTpOutComm: provided-interface=MdXX_SrcReqTp
      provided-com-specs:
        data-element=Md1_SrcTp, init-value=0
        data-element=Md{10..19}_SrcTp, init-value=0
        data-element=Md2_SrcTp, init-value=0
        data-element=Md{20..29}_SrcTp, init-value=0
        data-element=Md3_SrcTp, init-value=0
        data-element=Md{30..32}_SrcTp, init-value=0
        data-element=Md{4..9}_SrcTp, init-value=0
    5 x require port:
      KeSMSuRspStatHldTm: parameter-require-com-spec{init-value=100, parameter=KeSMSuRspStatHldTm/Val}, required-interface=KeSMSuRspStatHldTm
      MdXX_QuitArray: nonqueued-receiver-com-spec{data-element=MdXX_QuitArray/Val, filter=data-filter-type=ALWAYS, init-value=32 x 0}, required-interface=MdXX_QuitArray
      MdXX_SrcReqTpArray: nonqueued-receiver-com-spec{data-element=MdXX_SrcReqTpArray/Val, filter=data-filter-type=ALWAYS, init-value=32 x 0}, required-interface=MdXX_SrcReqTpArray
      MdXXIsTargetPosAlready: nonqueued-receiver-com-spec{data-element=IsTargetPos32Bit/Val, filter=data-filter-type=ALWAYS, init-value=0}, required-interface=IsTargetPos32Bit
      modestate32: nonqueued-receiver-com-spec{data-element=modestate32/Val, filter=data-filter-type=ALWAYS}, required-interface=modestate32
    behavior MdXX_RspOutComm_InternalBehavior
      operation invoked event OIT_MdXX_RspOutCommCalc_Cal_MdXX_RspOutCommCalc_Cal: start-on-event=MdXX_RspOutCommCalc_Cal, operation=MdXX_RspOutCommCalc.Cal
      runnable MdXX_RspOutCommCalc_Cal
        data-receive-point-by-arguments:
          4 x access:
            REC_MdXX_QuitArray_Val: accessed-variable=MdXX_QuitArray.Val
            REC_MdXX_SrcReqTpArray_Val: accessed-variable=MdXX_SrcReqTpArray.Val
            REC_MdXXIsTargetPosAlready_Val: accessed-variable=MdXXIsTargetPosAlready.Val
            REC_modestate32_Val: accessed-variable=modestate32.Val
        data-send-points:
          64 x access:
            SEND_MdXX_RspOutComm_Md1_RspOutComm: accessed-variable=MdXX_RspOutComm.Md1_RspOutComm
            SEND_MdXX_RspOutComm_Md{10..19}_RspOutComm: accessed-variable=MdXX_RspOutComm.Md{10..19}_RspOutComm
            SEND_MdXX_RspOutComm_Md2_RspOutComm: accessed-variable=MdXX_RspOutComm.Md2_RspOutComm
            SEND_MdXX_RspOutComm_Md{20..29}_RspOutComm: accessed-variable=MdXX_RspOutComm.Md{20..29}_RspOutComm
            SEND_MdXX_RspOutComm_Md3_RspOutComm: accessed-variable=MdXX_RspOutComm.Md3_RspOutComm
            SEND_MdXX_RspOutComm_Md{30..32}_RspOutComm: accessed-variable=MdXX_RspOutComm.Md{30..32}_RspOutComm
            SEND_MdXX_RspOutComm_Md{4..9}_RspOutComm: accessed-variable=MdXX_RspOutComm.Md{4..9}_RspOutComm
            SEND_MdXX_SrcReqTpOutComm_Md1_SrcTp: accessed-variable=MdXX_SrcReqTpOutComm.Md1_SrcTp
            SEND_MdXX_SrcReqTpOutComm_Md{10..19}_SrcTp: accessed-variable=MdXX_SrcReqTpOutComm.Md{10..19}_SrcTp
            SEND_MdXX_SrcReqTpOutComm_Md2_SrcTp: accessed-variable=MdXX_SrcReqTpOutComm.Md2_SrcTp
            SEND_MdXX_SrcReqTpOutComm_Md{20..29}_SrcTp: accessed-variable=MdXX_SrcReqTpOutComm.Md{20..29}_SrcTp
            SEND_MdXX_SrcReqTpOutComm_Md3_SrcTp: accessed-variable=MdXX_SrcReqTpOutComm.Md3_SrcTp
            SEND_MdXX_SrcReqTpOutComm_Md{30..32}_SrcTp: accessed-variable=MdXX_SrcReqTpOutComm.Md{30..32}_SrcTp
            SEND_MdXX_SrcReqTpOutComm_Md{4..9}_SrcTp: accessed-variable=MdXX_SrcReqTpOutComm.Md{4..9}_SrcTp
        parameter access PA_KeSMSuRspStatHldTm_Val: accessed-parameter=KeSMSuRspStatHldTm.Val
  application sw component type MdXX_RspToNetWork
    130 x provide port:
      IfVeSMStPassCmprtMd_RfCtrl_Sw_RclRspStat: nonqueued-sender-com-spec=data-element=MdRclRspStat/Val, provided-interface=MdRclRspStat
      IfVeSMSuHMI2L_StMd1_Rsp: nonqueued-sender-com-spec=data-element=HMI2LMdRsp/Val, provided-interface=HMI2LMdRsp
      IfVeSMSuHMI2L_StMd{10..19}_Rsp: nonqueued-sender-com-spec=data-element=HMI2LMdRsp/Val, provided-interface=HMI2LMdRsp
      IfVeSMSuHMI2L_StMd2_Rsp: nonqueued-sender-com-spec=data-element=HMI2LMdRsp/Val, provided-interface=HMI2LMdRsp
      IfVeSMSuHMI2L_StMd20_Rsp: nonqueued-sender-com-spec=data-element=HMI2LMdRsp/Val, provided-interface=HMI2LMdRsp
      IfVeSMSuHMI2L_StMd21_Rsp: nonqueued-sender-com-spec=data-element=HMI2LMdRsp/Val, provided-interface=HMI2LMdRsp
      IfVeSMSuHMI2L_StMd22_Rsp: nonqueued-sender-com-spec{data-element=HMI2LMdRsp/Val, init-value=0}, provided-interface=HMI2LMdRsp
      IfVeSMSuHMI2L_StMd{23..29}_Rsp: nonqueued-sender-com-spec=data-element=HMI2LMdRsp/Val, provided-interface=HMI2LMdRsp
      IfVeSMSuHMI2L_StMd3_Rsp: nonqueued-sender-com-spec=data-element=HMI2LMdRsp/Val, provided-interface=HMI2LMdRsp
      IfVeSMSuHMI2L_StMd{30..32}_Rsp: nonqueued-sender-com-spec=data-element=HMI2LMdRsp/Val, provided-interface=HMI2LMdRsp
      IfVeSMSuHMI2L_StMd{4..9}_Rsp: nonqueued-sender-com-spec=data-element=HMI2LMdRsp/Val, provided-interface=HMI2LMdRsp
      IfVeSMSuHMI2R_StMd1_Rsp: nonqueued-sender-com-spec=data-element=HMI2RMdRsp/Val, provided-interface=HMI2RMdRsp
      IfVeSMSuHMI2R_StMd{10..19}_Rsp: nonqueued-sender-com-spec=data-element=HMI2RMdRsp/Val, provided-interface=HMI2RMdRsp
      IfVeSMSuHMI2R_StMd2_Rsp: nonqueued-sender-com-spec=data-element=HMI2RMdRsp/Val, provided-interface=HMI2RMdRsp
      IfVeSMSuHMI2R_StMd{20..29}_Rsp: nonqueued-sender-com-spec=data-element=HMI2RMdRsp/Val, provided-interface=HMI2RMdRsp
      IfVeSMSuHMI2R_StMd3_Rsp: nonqueued-sender-com-spec=data-element=HMI2RMdRsp/Val, provided-interface=HMI2RMdRsp
      IfVeSMSuHMI2R_StMd{30..32}_Rsp: nonqueued-sender-com-spec=data-element=HMI2RMdRsp/Val, provided-interface=HMI2RMdRsp
      IfVeSMSuHMI2R_StMd{4..9}_Rsp: nonqueued-sender-com-spec=data-element=HMI2RMdRsp/Val, provided-interface=HMI2RMdRsp
      IfVeSMSuStPassCmprtMd{10..19}RclRspStat: nonqueued-sender-com-spec=data-element=MdRclRspStat/Val, provided-interface=MdRclRspStat
      IfVeSMSuStPassCmprtMd1RclRspStat: nonqueued-sender-com-spec=data-element=MdRclRspStat/Val, provided-interface=MdRclRspStat
      IfVeSMSuStPassCmprtMd{20..29}RclRspStat: nonqueued-sender-com-spec=data-element=MdRclRspStat/Val, provided-interface=MdRclRspStat
      IfVeSMSuStPassCmprtMd2RclRspStat: nonqueued-sender-com-spec=data-element=MdRclRspStat/Val, provided-interface=MdRclRspStat
      IfVeSMSuStPassCmprtMd{30..32}RclRspStat: nonqueued-sender-com-spec=data-element=MdRclRspStat/Val, provided-interface=MdRclRspStat
      IfVeSMSuStPassCmprtMd{3..9}RclRspStat: nonqueued-sender-com-spec=data-element=MdRclRspStat/Val, provided-interface=MdRclRspStat
      IfVeSMSuStSrv_StMd1_Rsp: nonqueued-sender-com-spec=data-element=StSrvMdRsp/Val, provided-interface=StSrvMdRsp
      IfVeSMSuStSrv_StMd{10..19}_Rsp: nonqueued-sender-com-spec=data-element=StSrvMdRsp/Val, provided-interface=StSrvMdRsp
      IfVeSMSuStSrv_StMd2_Rsp: nonqueued-sender-com-spec=data-element=StSrvMdRsp/Val, provided-interface=StSrvMdRsp
      IfVeSMSuStSrv_StMd{20..29}_Rsp: nonqueued-sender-com-spec=data-element=StSrvMdRsp/Val, provided-interface=StSrvMdRsp
      IfVeSMSuStSrv_StMd3_Rsp: nonqueued-sender-com-spec=data-element=StSrvMdRsp/Val, provided-interface=StSrvMdRsp
      IfVeSMSuStSrv_StMd{30..32}_Rsp: nonqueued-sender-com-spec=data-element=StSrvMdRsp/Val, provided-interface=StSrvMdRsp
      IfVeSMSuStSrv_StMd{4..9}_Rsp: nonqueued-sender-com-spec=data-element=StSrvMdRsp/Val, provided-interface=StSrvMdRsp
      MdXX_RspToNetWork: server-com-spec{operation=MdXX_RspToNetWork/Cal, queue-length=1}, provided-interface=MdXX_RspToNetWork
    require port MdXX_RspOutComm: required-interface=MdXX_RspOutComm
      required-com-specs:
        data-element=Md1_RspOutComm, filter=data-filter-type=ALWAYS, init-value=0
        data-element=Md{10..19}_RspOutComm, filter=data-filter-type=ALWAYS, init-value=0
        data-element=Md2_RspOutComm, filter=data-filter-type=ALWAYS, init-value=0
        data-element=Md{20..29}_RspOutComm, filter=data-filter-type=ALWAYS, init-value=0
        data-element=Md3_RspOutComm, filter=data-filter-type=ALWAYS, init-value=0
        data-element=Md{30..32}_RspOutComm, filter=data-filter-type=ALWAYS, init-value=0
        data-element=Md{4..9}_RspOutComm, filter=data-filter-type=ALWAYS, init-value=0
    require port MdXX_SrcReqTp: required-interface=MdXX_SrcReqTp
      required-com-specs:
        data-element=Md1_SrcTp, filter=data-filter-type=ALWAYS, init-value=0
        data-element=Md{10..19}_SrcTp, filter=data-filter-type=ALWAYS, init-value=0
        data-element=Md2_SrcTp, filter=data-filter-type=ALWAYS, init-value=0
        data-element=Md{20..29}_SrcTp, filter=data-filter-type=ALWAYS, init-value=0
        data-element=Md3_SrcTp, filter=data-filter-type=ALWAYS, init-value=0
        data-element=Md{30..32}_SrcTp, filter=data-filter-type=ALWAYS, init-value=0
        data-element=Md{4..9}_SrcTp, filter=data-filter-type=ALWAYS, init-value=0
    behavior MdXX_RspToNetWork_InternalBehavior
      operation invoked event OIT_MdXX_RspToNetWork_Cal_MdXX_RspToNetWork_Cal: start-on-event=MdXX_RspToNetWork_Cal, operation=MdXX_RspToNetWork.Cal
      runnable MdXX_RspToNetWork_Cal
        data-receive-point-by-arguments:
          64 x access:
            REC_MdXX_RspOutComm_Md1_RspOutComm: accessed-variable=MdXX_RspOutComm.Md1_RspOutComm
            REC_MdXX_RspOutComm_Md{10..19}_RspOutComm: accessed-variable=MdXX_RspOutComm.Md{10..19}_RspOutComm
            REC_MdXX_RspOutComm_Md2_RspOutComm: accessed-variable=MdXX_RspOutComm.Md2_RspOutComm
            REC_MdXX_RspOutComm_Md{20..29}_RspOutComm: accessed-variable=MdXX_RspOutComm.Md{20..29}_RspOutComm
            REC_MdXX_RspOutComm_Md3_RspOutComm: accessed-variable=MdXX_RspOutComm.Md3_RspOutComm
            REC_MdXX_RspOutComm_Md{30..32}_RspOutComm: accessed-variable=MdXX_RspOutComm.Md{30..32}_RspOutComm
            REC_MdXX_RspOutComm_Md{4..9}_RspOutComm: accessed-variable=MdXX_RspOutComm.Md{4..9}_RspOutComm
            REC_MdXX_SrcReqTp_Md1_SrcTp: accessed-variable=MdXX_SrcReqTp.Md1_SrcTp
            REC_MdXX_SrcReqTp_Md{10..19}_SrcTp: accessed-variable=MdXX_SrcReqTp.Md{10..19}_SrcTp
            REC_MdXX_SrcReqTp_Md2_SrcTp: accessed-variable=MdXX_SrcReqTp.Md2_SrcTp
            REC_MdXX_SrcReqTp_Md{20..29}_SrcTp: accessed-variable=MdXX_SrcReqTp.Md{20..29}_SrcTp
            REC_MdXX_SrcReqTp_Md3_SrcTp: accessed-variable=MdXX_SrcReqTp.Md3_SrcTp
            REC_MdXX_SrcReqTp_Md{30..32}_SrcTp: accessed-variable=MdXX_SrcReqTp.Md{30..32}_SrcTp
            REC_MdXX_SrcReqTp_Md{4..9}_SrcTp: accessed-variable=MdXX_SrcReqTp.Md{4..9}_SrcTp
        data-send-points:
          129 x access:
            SEND_IfVeSMStPassCmprtMd_RfCtrl_Sw_RclRspStat_Val: accessed-variable=IfVeSMStPassCmprtMd_RfCtrl_Sw_RclRspStat.Val
            SEND_IfVeSMSuHMI2L_StMd1_Rsp_Val: accessed-variable=IfVeSMSuHMI2L_StMd1_Rsp.Val
            SEND_IfVeSMSuHMI2L_StMd{10..19}_Rsp_Val: accessed-variable=IfVeSMSuHMI2L_StMd{10..19}_Rsp.Val
            SEND_IfVeSMSuHMI2L_StMd2_Rsp_Val: accessed-variable=IfVeSMSuHMI2L_StMd2_Rsp.Val
            SEND_IfVeSMSuHMI2L_StMd{20..29}_Rsp_Val: accessed-variable=IfVeSMSuHMI2L_StMd{20..29}_Rsp.Val
            SEND_IfVeSMSuHMI2L_StMd3_Rsp_Val: accessed-variable=IfVeSMSuHMI2L_StMd3_Rsp.Val
            SEND_IfVeSMSuHMI2L_StMd{30..32}_Rsp_Val: accessed-variable=IfVeSMSuHMI2L_StMd{30..32}_Rsp.Val
            SEND_IfVeSMSuHMI2L_StMd{4..9}_Rsp_Val: accessed-variable=IfVeSMSuHMI2L_StMd{4..9}_Rsp.Val
            SEND_IfVeSMSuHMI2R_StMd1_Rsp_Val: accessed-variable=IfVeSMSuHMI2R_StMd1_Rsp.Val
            SEND_IfVeSMSuHMI2R_StMd{10..19}_Rsp_Val: accessed-variable=IfVeSMSuHMI2R_StMd{10..19}_Rsp.Val
            SEND_IfVeSMSuHMI2R_StMd2_Rsp_Val: accessed-variable=IfVeSMSuHMI2R_StMd2_Rsp.Val
            SEND_IfVeSMSuHMI2R_StMd{20..29}_Rsp_Val: accessed-variable=IfVeSMSuHMI2R_StMd{20..29}_Rsp.Val
            SEND_IfVeSMSuHMI2R_StMd3_Rsp_Val: accessed-variable=IfVeSMSuHMI2R_StMd3_Rsp.Val
            SEND_IfVeSMSuHMI2R_StMd{30..32}_Rsp_Val: accessed-variable=IfVeSMSuHMI2R_StMd{30..32}_Rsp.Val
            SEND_IfVeSMSuHMI2R_StMd{4..9}_Rsp_Val: accessed-variable=IfVeSMSuHMI2R_StMd{4..9}_Rsp.Val
            SEND_IfVeSMSuStPassCmprtMd{10..19}RclRspStat_Val: accessed-variable=IfVeSMSuStPassCmprtMd{10..19}RclRspStat.Val
            SEND_IfVeSMSuStPassCmprtMd1RclRspStat_Val: accessed-variable=IfVeSMSuStPassCmprtMd1RclRspStat.Val
            SEND_IfVeSMSuStPassCmprtMd{20..29}RclRspStat_Val: accessed-variable=IfVeSMSuStPassCmprtMd{20..29}RclRspStat.Val
            SEND_IfVeSMSuStPassCmprtMd2RclRspStat_Val: accessed-variable=IfVeSMSuStPassCmprtMd2RclRspStat.Val
            SEND_IfVeSMSuStPassCmprtMd{30..32}RclRspStat_Val: accessed-variable=IfVeSMSuStPassCmprtMd{30..32}RclRspStat.Val
            SEND_IfVeSMSuStPassCmprtMd{3..9}RclRspStat_Val: accessed-variable=IfVeSMSuStPassCmprtMd{3..9}RclRspStat.Val
            SEND_IfVeSMSuStSrv_StMd1_Rsp_Val: accessed-variable=IfVeSMSuStSrv_StMd1_Rsp.Val
            SEND_IfVeSMSuStSrv_StMd{10..19}_Rsp_Val: accessed-variable=IfVeSMSuStSrv_StMd{10..19}_Rsp.Val
            SEND_IfVeSMSuStSrv_StMd2_Rsp_Val: accessed-variable=IfVeSMSuStSrv_StMd2_Rsp.Val
            SEND_IfVeSMSuStSrv_StMd{20..29}_Rsp_Val: accessed-variable=IfVeSMSuStSrv_StMd{20..29}_Rsp.Val
            SEND_IfVeSMSuStSrv_StMd3_Rsp_Val: accessed-variable=IfVeSMSuStSrv_StMd3_Rsp.Val
            SEND_IfVeSMSuStSrv_StMd{30..32}_Rsp_Val: accessed-variable=IfVeSMSuStSrv_StMd{30..32}_Rsp.Val
            SEND_IfVeSMSuStSrv_StMd{4..9}_Rsp_Val: accessed-variable=IfVeSMSuStSrv_StMd{4..9}_Rsp.Val
  application sw component type MdXX_Status
    provide port MdXX_Stat: provided-interface=MdXX_Stat
      provided-com-specs:
        data-element=Md1_Stat, init-value=0
        data-element=Md{10..19}_Stat, init-value=0
        data-element=Md2_Stat, init-value=0
        data-element=Md{20..29}_Stat, init-value=0
        data-element=Md3_Stat, init-value=0
        data-element=Md{30..32}_Stat, init-value=0
        data-element=Md{4..9}_Stat, init-value=0
    provide port MdXX_Status: server-com-spec{operation=MdXX_Status/Cal, queue-length=1}, provided-interface=MdXX_Status
    require port IsStBsy32Bit: nonqueued-receiver-com-spec{data-element=IsStBsy32Bit/Val, filter=data-filter-type=ALWAYS, init-value=0}, required-interface=IsStBsy32Bit
    require port MdXX_RspOutComm: required-interface=MdXX_RspOutComm
      required-com-specs:
        data-element=Md1_RspOutComm, filter=data-filter-type=ALWAYS, init-value=0
        data-element=Md{10..19}_RspOutComm, filter=data-filter-type=ALWAYS, init-value=0
        data-element=Md2_RspOutComm, filter=data-filter-type=ALWAYS, init-value=0
        data-element=Md{20..29}_RspOutComm, filter=data-filter-type=ALWAYS, init-value=0
        data-element=Md3_RspOutComm, filter=data-filter-type=ALWAYS, init-value=0
        data-element=Md{30..32}_RspOutComm, filter=data-filter-type=ALWAYS, init-value=0
        data-element=Md{4..9}_RspOutComm, filter=data-filter-type=ALWAYS, init-value=0
    require port MdXXIsTargetPosZone: nonqueued-receiver-com-spec{data-element=IsTargetPos32Bit/Val, filter=data-filter-type=ALWAYS, init-value=0}, required-interface=IsTargetPos32Bit
    behavior MdXX_Status_InternalBehavior
      operation invoked event OIT_MdXX_Status_Cal_MdXX_Status_Cal: start-on-event=MdXX_Status_Cal, operation=MdXX_Status.Cal
      runnable MdXX_Status_Cal
        data-receive-point-by-arguments:
          34 x access:
            REC_IsStBsy32Bit_Val: accessed-variable=IsStBsy32Bit.Val
            REC_MdXX_RspOutComm_Md1_RspOutComm: accessed-variable=MdXX_RspOutComm.Md1_RspOutComm
            REC_MdXX_RspOutComm_Md{10..19}_RspOutComm: accessed-variable=MdXX_RspOutComm.Md{10..19}_RspOutComm
            REC_MdXX_RspOutComm_Md2_RspOutComm: accessed-variable=MdXX_RspOutComm.Md2_RspOutComm
            REC_MdXX_RspOutComm_Md{20..29}_RspOutComm: accessed-variable=MdXX_RspOutComm.Md{20..29}_RspOutComm
            REC_MdXX_RspOutComm_Md3_RspOutComm: accessed-variable=MdXX_RspOutComm.Md3_RspOutComm
            REC_MdXX_RspOutComm_Md{30..32}_RspOutComm: accessed-variable=MdXX_RspOutComm.Md{30..32}_RspOutComm
            REC_MdXX_RspOutComm_Md{4..9}_RspOutComm: accessed-variable=MdXX_RspOutComm.Md{4..9}_RspOutComm
            REC_MdXXIsTargetPosZone_Val: accessed-variable=MdXXIsTargetPosZone.Val
        data-send-points:
          32 x access:
            SEND_MdXX_Stat_Md1_Stat: accessed-variable=MdXX_Stat.Md1_Stat
            SEND_MdXX_Stat_Md{10..19}_Stat: accessed-variable=MdXX_Stat.Md{10..19}_Stat
            SEND_MdXX_Stat_Md2_Stat: accessed-variable=MdXX_Stat.Md2_Stat
            SEND_MdXX_Stat_Md{20..29}_Stat: accessed-variable=MdXX_Stat.Md{20..29}_Stat
            SEND_MdXX_Stat_Md3_Stat: accessed-variable=MdXX_Stat.Md3_Stat
            SEND_MdXX_Stat_Md{30..32}_Stat: accessed-variable=MdXX_Stat.Md{30..32}_Stat
            SEND_MdXX_Stat_Md{4..9}_Stat: accessed-variable=MdXX_Stat.Md{4..9}_Stat
  application sw component type MdXX_StatusToNetWork
    45 x provide port:
      IfVeSMSuSRSCrt_MdSw1_Stat: nonqueued-sender-com-spec=data-element=SRSCrtMdStat_67_2/Val, provided-interface=SRSCrtMdStat_67_2
      IfVeSMSuSRSCrt_MdSw10_Stat: nonqueued-sender-com-spec=data-element=SRSCrtMdStat_67_2/Val, provided-interface=SRSCrtMdStat_67_2
      IfVeSMSuSRSCrt_MdSw{2..9}_Stat: nonqueued-sender-com-spec=data-element=SRSCrtMdStat_67_2/Val, provided-interface=SRSCrtMdStat_67_2
      IfVeSMSuSRSCrtMdIndTyp_67_2: nonqueued-sender-com-spec=data-element=SRSCrtMdIndTyp_67_2/Val, provided-interface=SRSCrtMdIndTyp_67_2
      IfVeSMSuStPassCmprtMd_Md1_CrtStat: nonqueued-sender-com-spec=data-element=StPassCmprtMdCrtMdStat/Val, provided-interface=StPassCmprtMdCrtMdStat
      IfVeSMSuStPassCmprtMd_Md{10..19}_CrtStat: nonqueued-sender-com-spec=data-element=StPassCmprtMdCrtMdStat/Val, provided-interface=StPassCmprtMdCrtMdStat
      IfVeSMSuStPassCmprtMd_Md2_CrtStat: nonqueued-sender-com-spec=data-element=StPassCmprtMdCrtMdStat/Val, provided-interface=StPassCmprtMdCrtMdStat
      IfVeSMSuStPassCmprtMd_Md{20..29}_CrtStat: nonqueued-sender-com-spec=data-element=StPassCmprtMdCrtMdStat/Val, provided-interface=StPassCmprtMdCrtMdStat
      IfVeSMSuStPassCmprtMd_Md3_CrtStat: nonqueued-sender-com-spec=data-element=StPassCmprtMdCrtMdStat/Val, provided-interface=StPassCmprtMdCrtMdStat
      IfVeSMSuStPassCmprtMd_Md{30..32}_CrtStat: nonqueued-sender-com-spec=data-element=StPassCmprtMdCrtMdStat/Val, provided-interface=StPassCmprtMdCrtMdStat
      IfVeSMSuStPassCmprtMd_Md{4..9}_CrtStat: nonqueued-sender-com-spec=data-element=StPassCmprtMdCrtMdStat/Val, provided-interface=StPassCmprtMdCrtMdStat
      IfVeSMSuStPassCmprtMdCrtMdStat: nonqueued-sender-com-spec{data-element=StPassCmprtMdCrtMdStat/Val, init-value=0}, provided-interface=StPassCmprtMdCrtMdStat
      MdXX_StatusToNetWork: server-com-spec{operation=MdXX_StatusToNetWork/Cal, queue-length=1}, provided-interface=MdXX_StatusToNetWork
    require port KeSMSbSRSPosNumConfig: parameter-require-com-spec{init-value=4, parameter=SRSPosNumConfig/Val}, required-interface=SRSPosNumConfig
    require port MdXX_Stat: required-interface=MdXX_Stat
      required-com-specs:
        data-element=Md1_Stat, filter=data-filter-type=ALWAYS, init-value=0
        data-element=Md{10..19}_Stat, filter=data-filter-type=ALWAYS, init-value=0
        data-element=Md2_Stat, filter=data-filter-type=ALWAYS, init-value=0
        data-element=Md{20..29}_Stat, filter=data-filter-type=ALWAYS, init-value=0
        data-element=Md3_Stat, filter=data-filter-type=ALWAYS, init-value=0
        data-element=Md{30..32}_Stat, filter=data-filter-type=ALWAYS, init-value=0
        data-element=Md{4..9}_Stat, filter=data-filter-type=ALWAYS, init-value=0
    require port PosArray: nonqueued-receiver-com-spec{data-element=PosArray/Val, filter=data-filter-type=ALWAYS, init-value=11 x 0}, required-interface=PosArray
    behavior MdXX_StatusToNetWork_InternalBehavior
      operation invoked event OIT_MdXX_StatusToNetWork_Cal_MdXX_StatusToNetWork_Cal: start-on-event=MdXX_StatusToNetWork_Cal, operation=MdXX_StatusToNetWork.Cal
      runnable MdXX_StatusToNetWork_Cal
        data-receive-point-by-arguments:
          33 x access:
            REC_MdXX_Stat_Md1_Stat: accessed-variable=MdXX_Stat.Md1_Stat
            REC_MdXX_Stat_Md{10..19}_Stat: accessed-variable=MdXX_Stat.Md{10..19}_Stat
            REC_MdXX_Stat_Md2_Stat: accessed-variable=MdXX_Stat.Md2_Stat
            REC_MdXX_Stat_Md{20..29}_Stat: accessed-variable=MdXX_Stat.Md{20..29}_Stat
            REC_MdXX_Stat_Md3_Stat: accessed-variable=MdXX_Stat.Md3_Stat
            REC_MdXX_Stat_Md{30..32}_Stat: accessed-variable=MdXX_Stat.Md{30..32}_Stat
            REC_MdXX_Stat_Md{4..9}_Stat: accessed-variable=MdXX_Stat.Md{4..9}_Stat
            REC_PosArray_Val: accessed-variable=PosArray.Val
        data-send-points:
          44 x access:
            SEND_IfVeSMSuSRSCrt_MdSw1_Stat_Val: accessed-variable=IfVeSMSuSRSCrt_MdSw1_Stat.Val
            SEND_IfVeSMSuSRSCrt_MdSw10_Stat_Val: accessed-variable=IfVeSMSuSRSCrt_MdSw10_Stat.Val
            SEND_IfVeSMSuSRSCrt_MdSw{2..9}_Stat_Val: accessed-variable=IfVeSMSuSRSCrt_MdSw{2..9}_Stat.Val
            SEND_IfVeSMSuSRSCrtMdIndTyp_67_2_Val: accessed-variable=IfVeSMSuSRSCrtMdIndTyp_67_2.Val
            SEND_IfVeSMSuStPassCmprtMd_Md1_CrtStat_Val: accessed-variable=IfVeSMSuStPassCmprtMd_Md1_CrtStat.Val
            SEND_IfVeSMSuStPassCmprtMd_Md{10..19}_CrtStat_Val: accessed-variable=IfVeSMSuStPassCmprtMd_Md{10..19}_CrtStat.Val
            SEND_IfVeSMSuStPassCmprtMd_Md2_CrtStat_Val: accessed-variable=IfVeSMSuStPassCmprtMd_Md2_CrtStat.Val
            SEND_IfVeSMSuStPassCmprtMd_Md{20..29}_CrtStat_Val: accessed-variable=IfVeSMSuStPassCmprtMd_Md{20..29}_CrtStat.Val
            SEND_IfVeSMSuStPassCmprtMd_Md3_CrtStat_Val: accessed-variable=IfVeSMSuStPassCmprtMd_Md3_CrtStat.Val
            SEND_IfVeSMSuStPassCmprtMd_Md{30..32}_CrtStat_Val: accessed-variable=IfVeSMSuStPassCmprtMd_Md{30..32}_CrtStat.Val
            SEND_IfVeSMSuStPassCmprtMd_Md{4..9}_CrtStat_Val: accessed-variable=IfVeSMSuStPassCmprtMd_Md{4..9}_CrtStat.Val
            SEND_IfVeSMSuStPassCmprtMdCrtMdStat_Val: accessed-variable=IfVeSMSuStPassCmprtMdCrtMdStat.Val
        parameter access PA_KeSMSbSRSPosNumConfig_Val: accessed-parameter=KeSMSbSRSPosNumConfig.Val
  application sw component type MdXXArray
    5 x provide port:
      MdXX_CommExitArray: nonqueued-sender-com-spec=data-element=MdXX_CommExitArray/Val, provided-interface=MdXX_CommExitArray
      MdXX_SoftIntArray: nonqueued-sender-com-spec{data-element=MdXX_SoftIntArray/Val, init-value=32 x 0}, provided-interface=MdXX_SoftIntArray
      MdXX_SrcReqTpArray: nonqueued-sender-com-spec{data-element=MdXX_SrcReqTpArray/Val, init-value=32 x 0}, provided-interface=MdXX_SrcReqTpArray
      MdXX_SWIntArray: nonqueued-sender-com-spec{data-element=MdXX_SWIntArray/Val, init-value=32 x 0}, provided-interface=MdXX_SWIntArray
      MdXXArray: server-com-spec{operation=MdXXArray/Cal, queue-length=1}, provided-interface=MdXXArray
    80 x require port:
      acsEntyMdSrcTp: nonqueued-receiver-com-spec{data-element=ModeSrcTp/Val, filter=data-filter-type=ALWAYS, init-value=0}, required-interface=ModeSrcTp
      acsExtMdSrcTp: nonqueued-receiver-com-spec{data-element=ModeSrcTp/Val, filter=data-filter-type=ALWAYS, init-value=0}, required-interface=ModeSrcTp
      AllLugSrcReqTp: nonqueued-receiver-com-spec{data-element=ModeSrcTp/Val, filter=data-filter-type=ALWAYS, init-value=0}, required-interface=ModeSrcTp
      AllVipSrcReqTp: nonqueued-receiver-com-spec{data-element=ModeSrcTp/Val, filter=data-filter-type=ALWAYS, init-value=0}, required-interface=ModeSrcTp
      CommExitCond: nonqueued-receiver-com-spec{data-element=CommExitCond/Val, filter=data-filter-type=ALWAYS, init-value=0}, required-interface=CommExitCond
      CommExitCondwithSpeed: nonqueued-receiver-com-spec{data-element=CommExitCondwithSpeed/Val, filter=data-filter-type=ALWAYS, init-value=0}, required-interface=CommExitCondwithSpeed
      EZE4sLMdSrcTp: nonqueued-receiver-com-spec{data-element=ModeSrcTp/Val, filter=data-filter-type=ALWAYS, init-value=0}, required-interface=ModeSrcTp
      EZE4sRMdSrcTp: nonqueued-receiver-com-spec{data-element=ModeSrcTp/Val, filter=data-filter-type=ALWAYS, init-value=0}, required-interface=ModeSrcTp
      EZQ4sLMdSrcTp: nonqueued-receiver-com-spec{data-element=ModeSrcTp/Val, filter=data-filter-type=ALWAYS, init-value=0}, required-interface=ModeSrcTp
      EZQ4sRMdSrcTp: nonqueued-receiver-com-spec{data-element=ModeSrcTp/Val, filter=data-filter-type=ALWAYS, init-value=0}, required-interface=ModeSrcTp
      IntimacyRtMdSrcTp: nonqueued-receiver-com-spec{data-element=ModeSrcTp/Val, filter=data-filter-type=ALWAYS, init-value=0}, required-interface=ModeSrcTp
      INTMSrcReqTp: nonqueued-receiver-com-spec{data-element=ModeSrcTp/Val, filter=data-filter-type=ALWAYS, init-value=0}, required-interface=ModeSrcTp
      LfFamlySrcReqTp: nonqueued-receiver-com-spec{data-element=ModeSrcTp/Val, filter=data-filter-type=ALWAYS, init-value=0}, required-interface=ModeSrcTp
      LfLySrcReqTp: nonqueued-receiver-com-spec{data-element=ModeSrcTp/Val, filter=data-filter-type=ALWAYS, init-value=0}, required-interface=ModeSrcTp
      LgrstCloseLtSrcReqTp: nonqueued-receiver-com-spec{data-element=ModeSrcTp/Val, filter=data-filter-type=ALWAYS, init-value=0}, required-interface=ModeSrcTp
      LgrstCloseRtSrcReqTp: nonqueued-receiver-com-spec{data-element=ModeSrcTp/Val, filter=data-filter-type=ALWAYS, init-value=0}, required-interface=ModeSrcTp
      LgrstOpenLtSrcReqTp: nonqueued-receiver-com-spec{data-element=ModeSrcTp/Val, filter=data-filter-type=ALWAYS, init-value=0}, required-interface=ModeSrcTp
      LgrstOpenRtSrcReqTp: nonqueued-receiver-com-spec{data-element=ModeSrcTp/Val, filter=data-filter-type=ALWAYS, init-value=0}, required-interface=ModeSrcTp
      LtLugSrcReqTp: nonqueued-receiver-com-spec{data-element=ModeSrcTp/Val, filter=data-filter-type=ALWAYS, init-value=0}, required-interface=ModeSrcTp
      LtRcvySrcReqTp: nonqueued-receiver-com-spec{data-element=ModeSrcTp/Val, filter=data-filter-type=ALWAYS, init-value=0}, required-interface=ModeSrcTp
      LtVipSrcReqTp: nonqueued-receiver-com-spec{data-element=ModeSrcTp/Val, filter=data-filter-type=ALWAYS, init-value=0}, required-interface=ModeSrcTp
      RtFamlySrcReqTp: nonqueued-receiver-com-spec{data-element=ModeSrcTp/Val, filter=data-filter-type=ALWAYS, init-value=0}, required-interface=ModeSrcTp
      RtLugSrcReqTp: nonqueued-receiver-com-spec{data-element=ModeSrcTp/Val, filter=data-filter-type=ALWAYS, init-value=0}, required-interface=ModeSrcTp
      RtLySrcReqTp: nonqueued-receiver-com-spec{data-element=ModeSrcTp/Val, filter=data-filter-type=ALWAYS, init-value=0}, required-interface=ModeSrcTp
      RtRcvySrcReqTp: nonqueued-receiver-com-spec{data-element=ModeSrcTp/Val, filter=data-filter-type=ALWAYS, init-value=0}, required-interface=ModeSrcTp
      RtVipSrcReqTp: nonqueued-receiver-com-spec{data-element=ModeSrcTp/Val, filter=data-filter-type=ALWAYS, init-value=0}, required-interface=ModeSrcTp
      SoftIntAcsEnty: nonqueued-receiver-com-spec{data-element=IntEnable/Val, filter=data-filter-type=ALWAYS, init-value=0}, required-interface=IntEnable
      SoftIntAcsExt: nonqueued-receiver-com-spec{data-element=IntEnable/Val, filter=data-filter-type=ALWAYS, init-value=0}, required-interface=IntEnable
      SoftIntAllLug: nonqueued-receiver-com-spec{data-element=IntEnable/Val, filter=data-filter-type=ALWAYS, init-value=0}, required-interface=IntEnable
      SoftIntAllVip: nonqueued-receiver-com-spec{data-element=IntEnable/Val, filter=data-filter-type=ALWAYS, init-value=0}, required-interface=IntEnable
      SoftIntEZE4sL: nonqueued-receiver-com-spec{data-element=IntEnable/Val, filter=data-filter-type=ALWAYS, init-value=0}, required-interface=IntEnable
      SoftIntEZE4sR: nonqueued-receiver-com-spec{data-element=IntEnable/Val, filter=data-filter-type=ALWAYS, init-value=0}, required-interface=IntEnable
      SoftIntEZQ4sL: nonqueued-receiver-com-spec{data-element=IntEnable/Val, filter=data-filter-type=ALWAYS, init-value=0}, required-interface=IntEnable
      SoftIntEZQ4sR: nonqueued-receiver-com-spec{data-element=IntEnable/Val, filter=data-filter-type=ALWAYS, init-value=0}, required-interface=IntEnable
      SoftIntIntimacyRt: nonqueued-receiver-com-spec{data-element=IntEnable/Val, filter=data-filter-type=ALWAYS, init-value=0}, required-interface=IntEnable
      SoftIntINTM: nonqueued-receiver-com-spec{data-element=IntEnable/Val, filter=data-filter-type=ALWAYS, init-value=0}, required-interface=IntEnable
      SoftIntLfFamly: nonqueued-receiver-com-spec{data-element=IntEnable/Val, filter=data-filter-type=ALWAYS, init-value=0}, required-interface=IntEnable
      SoftIntLfLug: nonqueued-receiver-com-spec{data-element=IntEnable/Val, filter=data-filter-type=ALWAYS, init-value=0}, required-interface=IntEnable
      SoftIntLfLy: nonqueued-receiver-com-spec{data-element=IntEnable/Val, filter=data-filter-type=ALWAYS, init-value=0}, required-interface=IntEnable
      SoftIntLfRcvy: nonqueued-receiver-com-spec{data-element=IntEnable/Val, filter=data-filter-type=ALWAYS, init-value=0}, required-interface=IntEnable
      SoftIntLfVip: nonqueued-receiver-com-spec{data-element=IntEnable/Val, filter=data-filter-type=ALWAYS, init-value=0}, required-interface=IntEnable
      SoftIntLgrstCloseLt: nonqueued-receiver-com-spec{data-element=IntEnable/Val, filter=data-filter-type=ALWAYS, init-value=0}, required-interface=IntEnable
      SoftIntLgrstCloseRt: nonqueued-receiver-com-spec{data-element=IntEnable/Val, filter=data-filter-type=ALWAYS, init-value=0}, required-interface=IntEnable
      SoftIntLgrstOpenLt: nonqueued-receiver-com-spec{data-element=IntEnable/Val, filter=data-filter-type=ALWAYS, init-value=0}, required-interface=IntEnable
      SoftIntLgrstOpenRt: nonqueued-receiver-com-spec{data-element=IntEnable/Val, filter=data-filter-type=ALWAYS, init-value=0}, required-interface=IntEnable
      SoftIntRtFamly: nonqueued-receiver-com-spec{data-element=IntEnable/Val, filter=data-filter-type=ALWAYS, init-value=0}, required-interface=IntEnable
      SoftIntRtLug: nonqueued-receiver-com-spec{data-element=IntEnable/Val, filter=data-filter-type=ALWAYS, init-value=0}, required-interface=IntEnable
      SoftIntRtLy: nonqueued-receiver-com-spec{data-element=IntEnable/Val, filter=data-filter-type=ALWAYS, init-value=0}, required-interface=IntEnable
      SoftIntRtRcvy: nonqueued-receiver-com-spec{data-element=IntEnable/Val, filter=data-filter-type=ALWAYS, init-value=0}, required-interface=IntEnable
      SoftIntRtVip: nonqueued-receiver-com-spec{data-element=IntEnable/Val, filter=data-filter-type=ALWAYS, init-value=0}, required-interface=IntEnable
      SoftIntWelcomeBkwd: nonqueued-receiver-com-spec{data-element=IntEnable/Val, filter=data-filter-type=ALWAYS, init-value=0}, required-interface=IntEnable
      SoftIntWelcomeFwd: nonqueued-receiver-com-spec{data-element=IntEnable/Val, filter=data-filter-type=ALWAYS, init-value=0}, required-interface=IntEnable
      SwIntAcsEnty: nonqueued-receiver-com-spec{data-element=IntEnable/Val, filter=data-filter-type=ALWAYS, init-value=0}, required-interface=IntEnable
      SwIntAcsExt: nonqueued-receiver-com-spec{data-element=IntEnable/Val, filter=data-filter-type=ALWAYS, init-value=0}, required-interface=IntEnable
      SwIntAllLug: nonqueued-receiver-com-spec{data-element=IntEnable/Val, filter=data-filter-type=ALWAYS, init-value=0}, required-interface=IntEnable
      SwIntAllVip: nonqueued-receiver-com-spec{data-element=IntEnable/Val, filter=data-filter-type=ALWAYS, init-value=0}, required-interface=IntEnable
      SwIntEZE4sL: nonqueued-receiver-com-spec{data-element=IntEnable/Val, filter=data-filter-type=ALWAYS, init-value=0}, required-interface=IntEnable
      SwIntEZE4sR: nonqueued-receiver-com-spec{data-element=IntEnable/Val, filter=data-filter-type=ALWAYS, init-value=0}, required-interface=IntEnable
      SwIntEZQ4sL: nonqueued-receiver-com-spec{data-element=IntEnable/Val, filter=data-filter-type=ALWAYS, init-value=0}, required-interface=IntEnable
      SwIntEZQ4sR: nonqueued-receiver-com-spec{data-element=IntEnable/Val, filter=data-filter-type=ALWAYS, init-value=0}, required-interface=IntEnable
      SwIntIntimacyRt: nonqueued-receiver-com-spec{data-element=IntEnable/Val, filter=data-filter-type=ALWAYS, init-value=0}, required-interface=IntEnable
      SwIntINTM: nonqueued-receiver-com-spec{data-element=IntEnable/Val, filter=data-filter-type=ALWAYS, init-value=0}, required-interface=IntEnable
      SwIntLfFamly: nonqueued-receiver-com-spec{data-element=IntEnable/Val, filter=data-filter-type=ALWAYS, init-value=0}, required-interface=IntEnable
      SwIntLfLug: nonqueued-receiver-com-spec{data-element=IntEnable/Val, filter=data-filter-type=ALWAYS, init-value=0}, required-interface=IntEnable
      SwIntLfLy: nonqueued-receiver-com-spec{data-element=IntEnable/Val, filter=data-filter-type=ALWAYS, init-value=0}, required-interface=IntEnable
      SwIntLfRcvy: nonqueued-receiver-com-spec{data-element=IntEnable/Val, filter=data-filter-type=ALWAYS, init-value=0}, required-interface=IntEnable
      SwIntLfVip: nonqueued-receiver-com-spec{data-element=IntEnable/Val, filter=data-filter-type=ALWAYS, init-value=0}, required-interface=IntEnable
      SwIntLgrstCloseLt: nonqueued-receiver-com-spec{data-element=IntEnable/Val, filter=data-filter-type=ALWAYS, init-value=0}, required-interface=IntEnable
      SwIntLgrstCloseRt: nonqueued-receiver-com-spec{data-element=IntEnable/Val, filter=data-filter-type=ALWAYS, init-value=0}, required-interface=IntEnable
      SwIntLgrstOpenLt: nonqueued-receiver-com-spec{data-element=IntEnable/Val, filter=data-filter-type=ALWAYS, init-value=0}, required-interface=IntEnable
      SwIntLgrstOpenRt: nonqueued-receiver-com-spec{data-element=IntEnable/Val, filter=data-filter-type=ALWAYS, init-value=0}, required-interface=IntEnable
      SwIntRtFamly: nonqueued-receiver-com-spec{data-element=IntEnable/Val, filter=data-filter-type=ALWAYS, init-value=0}, required-interface=IntEnable
      SwIntRtLug: nonqueued-receiver-com-spec{data-element=IntEnable/Val, filter=data-filter-type=ALWAYS, init-value=0}, required-interface=IntEnable
      SwIntRtLy: nonqueued-receiver-com-spec{data-element=IntEnable/Val, filter=data-filter-type=ALWAYS, init-value=0}, required-interface=IntEnable
      SwIntRtRcvy: nonqueued-receiver-com-spec{data-element=IntEnable/Val, filter=data-filter-type=ALWAYS, init-value=0}, required-interface=IntEnable
      SwIntRtVip: nonqueued-receiver-com-spec{data-element=IntEnable/Val, filter=data-filter-type=ALWAYS, init-value=0}, required-interface=IntEnable
      SwIntWelcomeBkwd: nonqueued-receiver-com-spec{data-element=IntEnable/Val, filter=data-filter-type=ALWAYS, init-value=0}, required-interface=IntEnable
      SwIntWelcomeFwd: nonqueued-receiver-com-spec{data-element=IntEnable/Val, filter=data-filter-type=ALWAYS, init-value=0}, required-interface=IntEnable
      WelcomeBkwdMdSrcTp: nonqueued-receiver-com-spec{data-element=ModeSrcTp/Val, filter=data-filter-type=ALWAYS, init-value=0}, required-interface=ModeSrcTp
      WelcomeFwdMdSrcTp: nonqueued-receiver-com-spec{data-element=ModeSrcTp/Val, filter=data-filter-type=ALWAYS, init-value=0}, required-interface=ModeSrcTp
    behavior MdXXArray_InternalBehavior
      operation invoked event OIT_MdXXArray_Cal_MdXXArray_Cal: start-on-event=MdXXArray_Cal, operation=MdXXArray.Cal
      runnable MdXXArray_Cal
        data-receive-point-by-arguments:
          80 x access:
            REC_acsEntyMdSrcTp_Val: accessed-variable=acsEntyMdSrcTp.Val
            REC_acsExtMdSrcTp_Val: accessed-variable=acsExtMdSrcTp.Val
            REC_AllLugSrcReqTp_Val: accessed-variable=AllLugSrcReqTp.Val
            REC_AllVipSrcReqTp_Val: accessed-variable=AllVipSrcReqTp.Val
            REC_CommExitCond_Val: accessed-variable=CommExitCond.Val
            REC_CommExitCondwithSpeed_Val: accessed-variable=CommExitCondwithSpeed.Val
            REC_EZE4sLMdSrcTp_Val: accessed-variable=EZE4sLMdSrcTp.Val
            REC_EZE4sRMdSrcTp_Val: accessed-variable=EZE4sRMdSrcTp.Val
            REC_EZQ4sLMdSrcTp_Val: accessed-variable=EZQ4sLMdSrcTp.Val
            REC_EZQ4sRMdSrcTp_Val: accessed-variable=EZQ4sRMdSrcTp.Val
            REC_IntimacyRtMdSrcTp_Val: accessed-variable=IntimacyRtMdSrcTp.Val
            REC_INTMSrcReqTp_Val: accessed-variable=INTMSrcReqTp.Val
            REC_LfFamlySrcReqTp_Val: accessed-variable=LfFamlySrcReqTp.Val
            REC_LfLySrcReqTp_Val: accessed-variable=LfLySrcReqTp.Val
            REC_LgrstCloseLtSrcReqTp_Val: accessed-variable=LgrstCloseLtSrcReqTp.Val
            REC_LgrstCloseRtSrcReqTp_Val: accessed-variable=LgrstCloseRtSrcReqTp.Val
            REC_LgrstOpenLtSrcReqTp_Val: accessed-variable=LgrstOpenLtSrcReqTp.Val
            REC_LgrstOpenRtSrcReqTp_Val: accessed-variable=LgrstOpenRtSrcReqTp.Val
            REC_LtLugSrcReqTp_Val: accessed-variable=LtLugSrcReqTp.Val
            REC_LtRcvySrcReqTp_Val: accessed-variable=LtRcvySrcReqTp.Val
            REC_LtVipSrcReqTp_Val: accessed-variable=LtVipSrcReqTp.Val
            REC_RtFamlySrcReqTp_Val: accessed-variable=RtFamlySrcReqTp.Val
            REC_RtLugSrcReqTp_Val: accessed-variable=RtLugSrcReqTp.Val
            REC_RtLySrcReqTp_Val: accessed-variable=RtLySrcReqTp.Val
            REC_RtRcvySrcReqTp_Val: accessed-variable=RtRcvySrcReqTp.Val
            REC_RtVipSrcReqTp_Val: accessed-variable=RtVipSrcReqTp.Val
            REC_SoftIntAcsEnty_Val: accessed-variable=SoftIntAcsEnty.Val
            REC_SoftIntAcsExt_Val: accessed-variable=SoftIntAcsExt.Val
            REC_SoftIntAllLug_Val: accessed-variable=SoftIntAllLug.Val
            REC_SoftIntAllVip_Val: accessed-variable=SoftIntAllVip.Val
            REC_SoftIntEZE4sL_Val: accessed-variable=SoftIntEZE4sL.Val
            REC_SoftIntEZE4sR_Val: accessed-variable=SoftIntEZE4sR.Val
            REC_SoftIntEZQ4sL_Val: accessed-variable=SoftIntEZQ4sL.Val
            REC_SoftIntEZQ4sR_Val: accessed-variable=SoftIntEZQ4sR.Val
            REC_SoftIntIntimacyRt_Val: accessed-variable=SoftIntIntimacyRt.Val
            REC_SoftIntINTM_Val: accessed-variable=SoftIntINTM.Val
            REC_SoftIntLfFamly_Val: accessed-variable=SoftIntLfFamly.Val
            REC_SoftIntLfLug_Val: accessed-variable=SoftIntLfLug.Val
            REC_SoftIntLfLy_Val: accessed-variable=SoftIntLfLy.Val
            REC_SoftIntLfRcvy_Val: accessed-variable=SoftIntLfRcvy.Val
            REC_SoftIntLfVip_Val: accessed-variable=SoftIntLfVip.Val
            REC_SoftIntLgrstCloseLt_Val: accessed-variable=SoftIntLgrstCloseLt.Val
            REC_SoftIntLgrstCloseRt_Val: accessed-variable=SoftIntLgrstCloseRt.Val
            REC_SoftIntLgrstOpenLt_Val: accessed-variable=SoftIntLgrstOpenLt.Val
            REC_SoftIntLgrstOpenRt_Val: accessed-variable=SoftIntLgrstOpenRt.Val
            REC_SoftIntRtFamly_Val: accessed-variable=SoftIntRtFamly.Val
            REC_SoftIntRtLug_Val: accessed-variable=SoftIntRtLug.Val
            REC_SoftIntRtLy_Val: accessed-variable=SoftIntRtLy.Val
            REC_SoftIntRtRcvy_Val: accessed-variable=SoftIntRtRcvy.Val
            REC_SoftIntRtVip_Val: accessed-variable=SoftIntRtVip.Val
            REC_SoftIntWelcomeBkwd_Val: accessed-variable=SoftIntWelcomeBkwd.Val
            REC_SoftIntWelcomeFwd_Val: accessed-variable=SoftIntWelcomeFwd.Val
            REC_SwIntAcsEnty_Val: accessed-variable=SwIntAcsEnty.Val
            REC_SwIntAcsExt_Val: accessed-variable=SwIntAcsExt.Val
            REC_SwIntAllLug_Val: accessed-variable=SwIntAllLug.Val
            REC_SwIntAllVip_Val: accessed-variable=SwIntAllVip.Val
            REC_SwIntEZE4sL_Val: accessed-variable=SwIntEZE4sL.Val
            REC_SwIntEZE4sR_Val: accessed-variable=SwIntEZE4sR.Val
            REC_SwIntEZQ4sL_Val: accessed-variable=SwIntEZQ4sL.Val
            REC_SwIntEZQ4sR_Val: accessed-variable=SwIntEZQ4sR.Val
            REC_SwIntIntimacyRt_Val: accessed-variable=SwIntIntimacyRt.Val
            REC_SwIntINTM_Val: accessed-variable=SwIntINTM.Val
            REC_SwIntLfFamly_Val: accessed-variable=SwIntLfFamly.Val
            REC_SwIntLfLug_Val: accessed-variable=SwIntLfLug.Val
            REC_SwIntLfLy_Val: accessed-variable=SwIntLfLy.Val
            REC_SwIntLfRcvy_Val: accessed-variable=SwIntLfRcvy.Val
            REC_SwIntLfVip_Val: accessed-variable=SwIntLfVip.Val
            REC_SwIntLgrstCloseLt_Val: accessed-variable=SwIntLgrstCloseLt.Val
            REC_SwIntLgrstCloseRt_Val: accessed-variable=SwIntLgrstCloseRt.Val
            REC_SwIntLgrstOpenLt_Val: accessed-variable=SwIntLgrstOpenLt.Val
            REC_SwIntLgrstOpenRt_Val: accessed-variable=SwIntLgrstOpenRt.Val
            REC_SwIntRtFamly_Val: accessed-variable=SwIntRtFamly.Val
            REC_SwIntRtLug_Val: accessed-variable=SwIntRtLug.Val
            REC_SwIntRtLy_Val: accessed-variable=SwIntRtLy.Val
            REC_SwIntRtRcvy_Val: accessed-variable=SwIntRtRcvy.Val
            REC_SwIntRtVip_Val: accessed-variable=SwIntRtVip.Val
            REC_SwIntWelcomeBkwd_Val: accessed-variable=SwIntWelcomeBkwd.Val
            REC_SwIntWelcomeFwd_Val: accessed-variable=SwIntWelcomeFwd.Val
            REC_WelcomeBkwdMdSrcTp_Val: accessed-variable=WelcomeBkwdMdSrcTp.Val
            REC_WelcomeFwdMdSrcTp_Val: accessed-variable=WelcomeFwdMdSrcTp.Val
        data-send-points:
          4 x access:
            SEND_MdXX_CommExitArray_Val: accessed-variable=MdXX_CommExitArray.Val
            SEND_MdXX_SoftIntArray_Val: accessed-variable=MdXX_SoftIntArray.Val
            SEND_MdXX_SrcReqTpArray_Val: accessed-variable=MdXX_SrcReqTpArray.Val
            SEND_MdXX_SWIntArray_Val: accessed-variable=MdXX_SWIntArray.Val
  application sw component type ModeRspCaller
    provide port ModeRsp: server-com-spec{operation=ModeRsp/Cal, queue-length=1}, provided-interface=ModeRsp
    8 x require port:
      CHM2Ctrl: client-com-spec=CHM2Ctrl/Cal, required-interface=CHM2Ctrl
      MdXX_RspOutCommCalc: client-com-spec=MdXX_RspOutCommCalc/Cal, required-interface=MdXX_RspOutCommCalc
      MdXX_RspToNetWork: client-com-spec=MdXX_RspToNetWork/Cal, required-interface=MdXX_RspToNetWork
      MdXX_Status: client-com-spec=MdXX_Status/Cal, required-interface=MdXX_Status
      MdXX_StatusToNetWork: client-com-spec=MdXX_StatusToNetWork/Cal, required-interface=MdXX_StatusToNetWork
      SRSModeState: client-com-spec=SRSModeState/Cal, required-interface=SRSModeState
      SRSSwIndCtrl: client-com-spec=SRSSwIndCtrl/Cal, required-interface=SRSSwIndCtrl
      StPassCmprtMdHMIDisCmdCalc: client-com-spec=StPassCmprtMdHMIDisCmdCalc/Cal, required-interface=StPassCmprtMdHMIDisCmdCalc
    behavior ModeRspCaller_InternalBehavior
      operation invoked event OIT_ModeRsp_Cal_ModeRsp_Cal: start-on-event=ModeRsp_Cal, operation=ModeRsp.Cal
      runnable ModeRsp_Cal
        8 x sync call, all with timeout=0:
          SC_CHM2Ctrl_Cal: operation=CHM2Ctrl.Cal
          SC_MdXX_RspOutCommCalc_Cal: operation=MdXX_RspOutCommCalc.Cal
          SC_MdXX_RspToNetWork_Cal: operation=MdXX_RspToNetWork.Cal
          SC_MdXX_Status_Cal: operation=MdXX_Status.Cal
          SC_MdXX_StatusToNetWork_Cal: operation=MdXX_StatusToNetWork.Cal
          SC_SRSModeState_Cal: operation=SRSModeState.Cal
          SC_SRSSwIndCtrl_Cal: operation=SRSSwIndCtrl.Cal
          SC_StPassCmprtMdHMIDisCmdCalc_Cal: operation=StPassCmprtMdHMIDisCmdCalc.Cal
  application sw component type ModeStatAndRspCaller
    require port ModeRsp: client-com-spec=ModeRsp/Cal, required-interface=ModeRsp
    require port ModeStateCtrl: client-com-spec=ModeStateCtrl/Cal, required-interface=ModeStateCtrl
    behavior ModeStatAndRspCaller_InternalBehavior
      timing event TMT_ModeStatAndRspRunnable: start-on-event=ModeStatAndRspRunnable, period=0.01
      runnable ModeStatAndRspRunnable
        sync call SC_ModeRsp_Cal: operation=ModeRsp.Cal, timeout=0
        sync call SC_ModeStateCtrl_Cal: operation=ModeStateCtrl.Cal, timeout=0
  application sw component type modestate32Calc
    provide port ModeState32: provided-interface=ModeState32Server
      provided-com-specs:
        operation=ModeState32Server/Clear, queue-length=1
        operation=ModeState32Server/Get, queue-length=1
        operation=ModeState32Server/Set, queue-length=1
    behavior modestate32Calc_InternalBehavior
      operation invoked event OIT_ModeState32_Clear_ModeState32_Clear: start-on-event=ModeState32_Clear, operation=ModeState32.Clear
      operation invoked event OIT_ModeState32_Get_ModeState32_Get: start-on-event=ModeState32_Get, operation=ModeState32.Get
      operation invoked event OIT_ModeState32_Set_ModeState32_Set: start-on-event=ModeState32_Set, operation=ModeState32.Set
      runnable ModeState32_Clear
      runnable ModeState32_Get
      runnable ModeState32_Set
  application sw component type ModeStateCtrlCaller
    provide port ModeStateCtrl: server-com-spec{operation=ModeStateCtrl/Cal, queue-length=1}, provided-interface=ModeStateCtrl
    5 x require port:
      MdEnAndBsyChk: client-com-spec=MdEnAndBsyChk/Cal, required-interface=MdEnAndBsyChk
      MdSWReqChk: client-com-spec=MdSWReqChk/Cal, required-interface=MdSWReqChk
      MdXX_QuitChk: client-com-spec=MdXX_QuitChk/Cal, required-interface=MdXX_QuitChk
      MdXXArray: client-com-spec=MdXXArray/Cal, required-interface=MdXXArray
      stateonoffchk: client-com-spec=stateonoffchk/Cal, required-interface=stateonoffchk
    behavior ModeStateCtrlCaller_InternalBehavior
      operation invoked event OIT_ModeStateCtrl_Cal_ModeStateCtrl_Cal: start-on-event=ModeStateCtrl_Cal, operation=ModeStateCtrl.Cal
      runnable ModeStateCtrl_Cal
        5 x sync call, all with timeout=0:
          SC_MdEnAndBsyChk_Cal: operation=MdEnAndBsyChk.Cal
          SC_MdSWReqChk_Cal: operation=MdSWReqChk.Cal
          SC_MdXX_QuitChk_Cal: operation=MdXX_QuitChk.Cal
          SC_MdXXArray_Cal: operation=MdXXArray.Cal
          SC_stateonoffchk_Cal: operation=stateonoffchk.Cal
  application sw component type SRSModeState
    4 x provide port:
      ModeSrcTpLt: nonqueued-sender-com-spec{data-element=ModeSrcTp/Val, init-value=0}, provided-interface=ModeSrcTp
      oModeState: nonqueued-sender-com-spec=data-element=ModeState/Val, provided-interface=ModeState
      SRSMode: nonqueued-sender-com-spec{data-element=SRSCurMode2/Val, init-value=0}, provided-interface=SRSCurMode2
      SRSModeState: server-com-spec{operation=SRSModeState/Cal, queue-length=1}, provided-interface=SRSModeState
    4 x require port:
      KeSMSuMdNums: parameter-require-com-spec{init-value=26, parameter=KeSMSuMdNums/Val}, required-interface=KeSMSuMdNums
      MdXX_SrcReqTp: required-interface=MdXX_SrcReqTp
        required-com-specs:
          data-element=Md1_SrcTp, filter=data-filter-type=ALWAYS, init-value=0
          data-element=Md{10..19}_SrcTp, filter=data-filter-type=ALWAYS, init-value=0
          data-element=Md2_SrcTp, filter=data-filter-type=ALWAYS, init-value=0
          data-element=Md{20..29}_SrcTp, filter=data-filter-type=ALWAYS, init-value=0
          data-element=Md3_SrcTp, filter=data-filter-type=ALWAYS, init-value=0
          data-element=Md{30..32}_SrcTp, filter=data-filter-type=ALWAYS, init-value=0
          data-element=Md{4..9}_SrcTp, filter=data-filter-type=ALWAYS, init-value=0
      modestate32: nonqueued-receiver-com-spec{data-element=modestate32/Val, filter=data-filter-type=ALWAYS, init-value=0}, required-interface=modestate32
      SRSconvertArray: parameter-require-com-spec{init-value=[0, 1, 5, 8, 2, 9, 10, 11, 6, 7, 3, 12, 4, 13, 14, 15, 16, 17, 18, 19, 20, 21, 22, 23, 24, 25, 26, 27, 28, 29, 30, 31], parameter=SRSconvertArray/Val}, required-interface=SRSconvertArray
    behavior SRSModeState_InternalBehavior
      operation invoked event OIT_SRSModeState_Cal_SRSModeState_Cal: start-on-event=SRSModeState_Cal, operation=SRSModeState.Cal
      runnable SRSModeState_Cal
        data-receive-point-by-arguments:
          33 x access:
            REC_MdXX_SrcReqTp_Md1_SrcTp: accessed-variable=MdXX_SrcReqTp.Md1_SrcTp
            REC_MdXX_SrcReqTp_Md{10..19}_SrcTp: accessed-variable=MdXX_SrcReqTp.Md{10..19}_SrcTp
            REC_MdXX_SrcReqTp_Md2_SrcTp: accessed-variable=MdXX_SrcReqTp.Md2_SrcTp
            REC_MdXX_SrcReqTp_Md{20..29}_SrcTp: accessed-variable=MdXX_SrcReqTp.Md{20..29}_SrcTp
            REC_MdXX_SrcReqTp_Md3_SrcTp: accessed-variable=MdXX_SrcReqTp.Md3_SrcTp
            REC_MdXX_SrcReqTp_Md{30..32}_SrcTp: accessed-variable=MdXX_SrcReqTp.Md{30..32}_SrcTp
            REC_MdXX_SrcReqTp_Md{4..9}_SrcTp: accessed-variable=MdXX_SrcReqTp.Md{4..9}_SrcTp
            REC_modestate32_Val: accessed-variable=modestate32.Val
        data-send-points:
          access SEND_ModeSrcTpLt_Val: accessed-variable=ModeSrcTpLt.Val
          access SEND_oModeState_Val: accessed-variable=oModeState.Val
          access SEND_SRSMode_Val: accessed-variable=SRSMode.Val
        parameter access PA_KeSMSuMdNums_Val: accessed-parameter=KeSMSuMdNums.Val
        parameter access PA_SRSconvertArray_Val: accessed-parameter=SRSconvertArray.Val
  application sw component type SRSSwIndCtrl
    14 x provide port:
      IfVeSMSuSRSCrt_MdSw1_Stat: nonqueued-sender-com-spec{data-element=SRSCrtMdStat_67_2/Val, init-value=0}, provided-interface=SRSCrtMdStat_67_2
      IfVeSMSuSRSCrt_MdSw10_Stat: nonqueued-sender-com-spec{data-element=SRSCrtMdStat_67_2/Val, init-value=0}, provided-interface=SRSCrtMdStat_67_2
      IfVeSMSuSRSCrt_MdSw{2..9}_Stat: nonqueued-sender-com-spec{data-element=SRSCrtMdStat_67_2/Val, init-value=0}, provided-interface=SRSCrtMdStat_67_2
      IfVeSMSuSRSCrtMdIndTyp_67_2: nonqueued-sender-com-spec{data-element=SRSCrtMdIndTyp_67_2/Val, init-value=0}, provided-interface=SRSCrtMdIndTyp_67_2
      IfVeSMSuSRSMdSlctSwIndTyp_67_2: nonqueued-sender-com-spec{data-element=SRSMdSlctSwIndTyp_67_2/Val, init-value=1}, provided-interface=SRSMdSlctSwIndTyp_67_2
      SRSMdSlctSwStat_67_2: nonqueued-sender-com-spec{data-element=SRSMdSlctSwStat_67_2/Val, init-value=0}, provided-interface=SRSMdSlctSwStat_67_2
      SRSSwIndCtrl: server-com-spec{operation=SRSSwIndCtrl/Cal, queue-length=1}, provided-interface=SRSSwIndCtrl
    15 x require port:
      IfVeSMStPassCmprtMd_RfCtrl_Sw_RclRspStat: nonqueued-receiver-com-spec{data-element=MdRclRspStat/Val, filter=data-filter-type=ALWAYS, init-value=0}, required-interface=MdRclRspStat
      IfVeSMSuSRSCrt_MdSw1_Stat_In: nonqueued-receiver-com-spec{data-element=SRSCrtMdStat_67_2/Val, filter=data-filter-type=ALWAYS, init-value=0}, required-interface=SRSCrtMdStat_67_2
      IfVeSMSuSRSCrt_MdSw10_Stat_In: nonqueued-receiver-com-spec{data-element=SRSCrtMdStat_67_2/Val, filter=data-filter-type=ALWAYS, init-value=0}, required-interface=SRSCrtMdStat_67_2
      IfVeSMSuSRSCrt_MdSw{2..9}_Stat_In: nonqueued-receiver-com-spec{data-element=SRSCrtMdStat_67_2/Val, filter=data-filter-type=ALWAYS, init-value=0}, required-interface=SRSCrtMdStat_67_2
      IfVeSMSuSRSCrtMdIndTyp_67_2_In: nonqueued-receiver-com-spec{data-element=SRSCrtMdIndTyp_67_2/Val, filter=data-filter-type=ALWAYS, init-value=0}, required-interface=SRSCrtMdIndTyp_67_2
      IfVeSMSuSRSMdSlctSwIndTyp_67_2_In: nonqueued-receiver-com-spec{data-element=SRSMdSlctSwIndTyp_67_2/Val, filter=data-filter-type=ALWAYS, init-value=1}, required-interface=SRSMdSlctSwIndTyp_67_2
      KeSMSuSRSMdSlctSwDurnTm: parameter-require-com-spec{init-value=20, parameter=KeSMSuSRSMdSlctSwDurnTm/Val}, required-interface=KeSMSuSRSMdSlctSwDurnTm
      SRSMdSlctSwStat_67_2_In: nonqueued-receiver-com-spec{data-element=SRSMdSlctSwStat_67_2/Val, filter=data-filter-type=ALWAYS, init-value=0}, required-interface=SRSMdSlctSwStat_67_2
    behavior SRSSwIndCtrl_InternalBehavior
      operation invoked event OIT_SRSSwIndCtrl_Cal_SRSSwIndCtrl_Cal: start-on-event=SRSSwIndCtrl_Cal, operation=SRSSwIndCtrl.Cal
      runnable SRSSwIndCtrl_Cal
        data-receive-point-by-arguments:
          14 x access:
            REC_IfVeSMStPassCmprtMd_RfCtrl_Sw_RclRspStat_Val: accessed-variable=IfVeSMStPassCmprtMd_RfCtrl_Sw_RclRspStat.Val
            REC_IfVeSMSuSRSCrt_MdSw1_Stat_In_Val: accessed-variable=IfVeSMSuSRSCrt_MdSw1_Stat_In.Val
            REC_IfVeSMSuSRSCrt_MdSw10_Stat_In_Val: accessed-variable=IfVeSMSuSRSCrt_MdSw10_Stat_In.Val
            REC_IfVeSMSuSRSCrt_MdSw{2..9}_Stat_In_Val: accessed-variable=IfVeSMSuSRSCrt_MdSw{2..9}_Stat_In.Val
            REC_IfVeSMSuSRSCrtMdIndTyp_67_2_In_Val: accessed-variable=IfVeSMSuSRSCrtMdIndTyp_67_2_In.Val
            REC_IfVeSMSuSRSMdSlctSwIndTyp_67_2_In_Val: accessed-variable=IfVeSMSuSRSMdSlctSwIndTyp_67_2_In.Val
            REC_SRSMdSlctSwStat_67_2_In_Val: accessed-variable=SRSMdSlctSwStat_67_2_In.Val
        data-send-points:
          13 x access:
            SEND_IfVeSMSuSRSCrt_MdSw1_Stat_Val: accessed-variable=IfVeSMSuSRSCrt_MdSw1_Stat.Val
            SEND_IfVeSMSuSRSCrt_MdSw10_Stat_Val: accessed-variable=IfVeSMSuSRSCrt_MdSw10_Stat.Val
            SEND_IfVeSMSuSRSCrt_MdSw{2..9}_Stat_Val: accessed-variable=IfVeSMSuSRSCrt_MdSw{2..9}_Stat.Val
            SEND_IfVeSMSuSRSCrtMdIndTyp_67_2_Val: accessed-variable=IfVeSMSuSRSCrtMdIndTyp_67_2.Val
            SEND_IfVeSMSuSRSMdSlctSwIndTyp_67_2_Val: accessed-variable=IfVeSMSuSRSMdSlctSwIndTyp_67_2.Val
            SEND_SRSMdSlctSwStat_67_2_Val: accessed-variable=SRSMdSlctSwStat_67_2.Val
        parameter access PA_KeSMSuSRSMdSlctSwDurnTm_Val: accessed-parameter=KeSMSuSRSMdSlctSwDurnTm.Val
  application sw component type StateOnOffChk
    provide port stateonoffchk: server-com-spec{operation=stateonoffchk/Cal, queue-length=1}, provided-interface=stateonoffchk
    require port CommCond: nonqueued-receiver-com-spec{data-element=CommCond/Val, filter=data-filter-type=ALWAYS, init-value=0}, required-interface=CommCond
    behavior StateOnOffChk_InternalBehavior
      operation invoked event OIT_stateonoffchk_Cal_stateonoffchk_Cal: start-on-event=stateonoffchk_Cal, operation=stateonoffchk.Cal
      runnable stateonoffchk_Cal
        data-receive-point-by-arguments:
          access REC_CommCond_Val: accessed-variable=CommCond.Val
  application sw component type StPassCmprtMdHMIDisCmd
    provide port IfVeSMSuStPassCmprtMdHMIDisCmd: nonqueued-sender-com-spec=data-element=StPassCmprtMdHMIDisCmdSrv/Val, provided-interface=StPassCmprtMdHMIDisCmdSrv
    provide port StPassCmprtMdHMIDisCmdCalc: server-com-spec{operation=StPassCmprtMdHMIDisCmdCalc/Cal, queue-length=1}, provided-interface=StPassCmprtMdHMIDisCmdCalc
    require port modestate32: nonqueued-receiver-com-spec{data-element=modestate32/Val, filter=data-filter-type=ALWAYS, init-value=0}, required-interface=modestate32
    require port PwrMdChked: nonqueued-receiver-com-spec{data-element=PowerMode/Val, filter=data-filter-type=ALWAYS}, required-interface=PowerMode
    behavior StPassCmprtMdHMIDisCmd_InternalBehavior
      operation invoked event OIT_StPassCmprtMdHMIDisCmdCalc_Cal_StPassCmprtMdHMIDisCmdCalc_Cal: start-on-event=StPassCmprtMdHMIDisCmdCalc_Cal, operation=StPassCmprtMdHMIDisCmdCalc.Cal
      runnable StPassCmprtMdHMIDisCmdCalc_Cal
        data-receive-point-by-arguments:
          access REC_modestate32_Val: accessed-variable=modestate32.Val
          access REC_PwrMdChked_Val: accessed-variable=PwrMdChked.Val
        data-send-points:
          access SEND_IfVeSMSuStPassCmprtMdHMIDisCmd_Val: accessed-variable=IfVeSMSuStPassCmprtMdHMIDisCmd.Val
  composition sw component type CHM2Ctrl
    provide port CHM2Ctrl: server-com-spec{operation=CHM2Ctrl/Cal, queue-length=1}, provided-interface=CHM2Ctrl
    provide port IfVeSMSeStPassCmprtMdNoti2ChmEvntStat: nonqueued-sender-com-spec=data-element=ChmEvenState/Val, provided-interface=ChmEvenState
    5 x require port:
      IfVeSMSuChmMgrStat: nonqueued-receiver-com-spec{data-element=IfVeSMSuChmMgrStat/Val, filter=data-filter-type=ALWAYS}, required-interface=IfVeSMSuChmMgrStat
      KeSMSbMdChime2Enable: parameter-require-com-spec{init-value=0, parameter=MdChime2Enable/Val}, required-interface=MdChime2Enable
      KeSMSuChmReqDurnTm: parameter-require-com-spec{init-value=200, parameter=KeSMSuChmReqDurnTm/Val}, required-interface=KeSMSuChmReqDurnTm
      KeSMSuChmReqIntlTm: parameter-require-com-spec{init-value=50, parameter=KeSMSuChmReqIntlTm/Val}, required-interface=KeSMSuChmReqIntlTm
      modestate32: nonqueued-receiver-com-spec{data-element=modestate32/Val, filter=data-filter-type=ALWAYS, init-value=0}, required-interface=modestate32
    4 x component:
      CHM2ActiveReqChk: type=CHM2ActiveReqChk
      CHM2ActiveSubStateCtrl: type=CHM2ActiveSubStateCtrl
      CHM2Ctrl_Caller: type=CHM2Ctrl_Caller
      CHM2StateCtrl: type=CHM2StateCtrl
    connect CHM2ActiveReqChk.CHM2ActiveReqChk -> CHM2Ctrl_Caller.CHM2ActiveReqChk
    connect CHM2ActiveReqChk.CHM2ActiveReq -> CHM2StateCtrl.CHM2ActiveReq
    connect CHM2ActiveSubStateCtrl.CHM2ActiveSubStateCtrl -> CHM2Ctrl_Caller.CHM2ActiveSubStateCtrl
    connect CHM2StateCtrl.CHM2ActiveSubState -> CHM2ActiveSubStateCtrl.CHM2ActiveSubState
    connect CHM2StateCtrl.IfVeSMSeStPassCmprtMdNoti2ChmEvntStatLocal -> CHM2ActiveSubStateCtrl.IfVeSMSeStPassCmprtMdNoti2ChmEvntStatLocal
    connect CHM2StateCtrl.CHM2StateCtrl -> CHM2Ctrl_Caller.CHM2StateCtrl
    delegate CHM2Ctrl_Caller.CHM2Ctrl <-> outer port CHM2Ctrl/CHM2Ctrl
    delegate CHM2ActiveSubStateCtrl.IfVeSMSeStPassCmprtMdNoti2ChmEvntStat <-> outer port CHM2Ctrl/IfVeSMSeStPassCmprtMdNoti2ChmEvntStat
    delegate CHM2StateCtrl.IfVeSMSuChmMgrStat <-> outer port CHM2Ctrl/IfVeSMSuChmMgrStat
    delegate CHM2ActiveSubStateCtrl.IfVeSMSuChmMgrStat <-> outer port CHM2Ctrl/IfVeSMSuChmMgrStat
    delegate CHM2Ctrl_Caller.KeSMSbMdChime2Enable <-> outer port CHM2Ctrl/KeSMSbMdChime2Enable
    delegate CHM2StateCtrl.KeSMSuChmReqDurnTm <-> outer port CHM2Ctrl/KeSMSuChmReqDurnTm
    delegate CHM2ActiveSubStateCtrl.KeSMSuChmReqDurnTm <-> outer port CHM2Ctrl/KeSMSuChmReqDurnTm
    delegate CHM2ActiveSubStateCtrl.KeSMSuChmReqIntlTm <-> outer port CHM2Ctrl/KeSMSuChmReqIntlTm
    delegate CHM2ActiveReqChk.modestate32 <-> outer port CHM2Ctrl/modestate32
  composition sw component type MdEnCtrlAndBsyChk
    provide port IsStBsy32Bit: nonqueued-sender-com-spec{data-element=IsStBsy32Bit/Val, init-value=0}, provided-interface=IsStBsy32Bit
    provide port MdEnAndBsyChk: server-com-spec{operation=MdEnAndBsyChk/Cal, queue-length=1}, provided-interface=MdEnAndBsyChk
    provide port modestate32: nonqueued-sender-com-spec{data-element=modestate32/Val, init-value=0}, provided-interface=modestate32
    7 x require port:
      ChkBsyBitArray: nonqueued-receiver-com-spec{data-element=ChkBsyBitArray/Val, filter=data-filter-type=ALWAYS}, required-interface=ChkBsyBitArray
      MdReqArray: nonqueued-receiver-com-spec{data-element=MdReqArray/Val, filter=data-filter-type=ALWAYS}, required-interface=MdReqArray
      MdXX_Quit32bit: nonqueued-receiver-com-spec{data-element=MdXX_Quit32bit/Val, filter=data-filter-type=ALWAYS, init-value=0}, required-interface=MdXX_Quit32bit
      SetBsyBitArray: nonqueued-receiver-com-spec{data-element=SetBsyBitArray/Val, filter=data-filter-type=ALWAYS}, required-interface=SetBsyBitArray
      SetEnBitArray: nonqueued-receiver-com-spec{data-element=SetEnBitArray/Val, filter=data-filter-type=ALWAYS}, required-interface=SetEnBitArray
      StNumFlg: required-interface=StNumFlg
        required-com-specs:
          data-element=Is4s, filter=data-filter-type=ALWAYS, init-value=0
          data-element=Is6s, filter=data-filter-type=ALWAYS, init-value=0
          data-element=Is6s7s, filter=data-filter-type=ALWAYS, init-value=0
          data-element=Is7s, filter=data-filter-type=ALWAYS, init-value=0
      VeSMSuMdNum: nonqueued-receiver-com-spec{data-element=VeSMSuMdNum/Val, filter=data-filter-type=ALWAYS}, required-interface=VeSMSuMdNum
    7 x component:
      IsStBsy32BitCalc: type=IsStBsy32BitCalc
      MdBsyClear4s: type=MdBsyClear4s
      MdBsyClear6s7s: type=MdBsyClear6s7s
      MdEnAndBsyChk_Caller: type=MdEnAndBsyChk_Caller
      MdEnChk: type=MdEnChk
      MdEnClear: type=MdEnClear
      modestate32Calc: type=modestate32Calc
    connect IsStBsy32BitCalc.IsStBsy32 -> MdBsyClear4s.IsStBsy32
    connect IsStBsy32BitCalc.IsStBsy32 -> MdBsyClear6s7s.IsStBsy32
    connect IsStBsy32BitCalc.IsStBsy32 -> MdEnAndBsyChk_Caller.IsStBsy32
    connect IsStBsy32BitCalc.IsStBsy32 -> MdEnChk.IsStBsy32
    connect MdBsyClear4s.MdBsyClear4s -> MdEnAndBsyChk_Caller.MdBsyClear4s
    connect MdBsyClear6s7s.MdBsyClear6s7s -> MdEnAndBsyChk_Caller.MdBsyClear6s7s
    connect MdEnChk.MdEnChk -> MdEnAndBsyChk_Caller.MdEnChk
    connect MdEnClear.MdEnClear -> MdEnAndBsyChk_Caller.MdEnClear
    connect modestate32Calc.ModeState32 -> MdBsyClear4s.ModeState32
    connect modestate32Calc.ModeState32 -> MdBsyClear6s7s.ModeState32
    connect modestate32Calc.ModeState32 -> MdEnAndBsyChk_Caller.ModeState32
    connect modestate32Calc.ModeState32 -> MdEnChk.ModeState32
    connect modestate32Calc.ModeState32 -> MdEnClear.ModeState32
    delegate MdEnChk.ChkBsyBitArray <-> outer port MdEnCtrlAndBsyChk/ChkBsyBitArray
    delegate MdEnAndBsyChk_Caller.IsStBsy32Bit <-> outer port MdEnCtrlAndBsyChk/IsStBsy32Bit
    delegate MdEnAndBsyChk_Caller.MdEnAndBsyChk <-> outer port MdEnCtrlAndBsyChk/MdEnAndBsyChk
    delegate MdEnChk.MdReqArray <-> outer port MdEnCtrlAndBsyChk/MdReqArray
    delegate MdEnClear.MdXX_Quit32bit <-> outer port MdEnCtrlAndBsyChk/MdXX_Quit32bit
    delegate MdEnAndBsyChk_Caller.modestate32Bit <-> outer port MdEnCtrlAndBsyChk/modestate32
    delegate MdEnChk.SetBsyBitArray <-> outer port MdEnCtrlAndBsyChk/SetBsyBitArray
    delegate MdEnChk.SetEnBitArray <-> outer port MdEnCtrlAndBsyChk/SetEnBitArray
    delegate MdEnAndBsyChk_Caller.StNumFlg <-> outer port MdEnCtrlAndBsyChk/StNumFlg
    delegate MdBsyClear6s7s.StNumFlg <-> outer port MdEnCtrlAndBsyChk/StNumFlg
    delegate MdEnChk.VeSMSuMdNum <-> outer port MdEnCtrlAndBsyChk/VeSMSuMdNum
  composition sw component type ModeRsp
    181 x provide port:
      IfVeSMSeStPassCmprtMdNoti2ChmEvntStat: nonqueued-sender-com-spec=data-element=ChmEvenState/Val, provided-interface=ChmEvenState
      IfVeSMStPassCmprtMd_RfCtrl_Sw_RclRspStat: nonqueued-sender-com-spec=data-element=MdRclRspStat/Val, provided-interface=MdRclRspStat
      IfVeSMSuHMI2L_StMd1_Rsp: nonqueued-sender-com-spec=data-element=HMI2LMdRsp/Val, provided-interface=HMI2LMdRsp
      IfVeSMSuHMI2L_StMd{10..19}_Rsp: nonqueued-sender-com-spec=data-element=HMI2LMdRsp/Val, provided-interface=HMI2LMdRsp
      IfVeSMSuHMI2L_StMd2_Rsp: nonqueued-sender-com-spec=data-element=HMI2LMdRsp/Val, provided-interface=HMI2LMdRsp
      IfVeSMSuHMI2L_StMd20_Rsp: nonqueued-sender-com-spec=data-element=HMI2LMdRsp/Val, provided-interface=HMI2LMdRsp
      IfVeSMSuHMI2L_StMd21_Rsp: nonqueued-sender-com-spec=data-element=HMI2LMdRsp/Val, provided-interface=HMI2LMdRsp
      IfVeSMSuHMI2L_StMd22_Rsp: nonqueued-sender-com-spec{data-element=HMI2LMdRsp/Val, init-value=0}, provided-interface=HMI2LMdRsp
      IfVeSMSuHMI2L_StMd{23..29}_Rsp: nonqueued-sender-com-spec=data-element=HMI2LMdRsp/Val, provided-interface=HMI2LMdRsp
      IfVeSMSuHMI2L_StMd3_Rsp: nonqueued-sender-com-spec=data-element=HMI2LMdRsp/Val, provided-interface=HMI2LMdRsp
      IfVeSMSuHMI2L_StMd{30..32}_Rsp: nonqueued-sender-com-spec=data-element=HMI2LMdRsp/Val, provided-interface=HMI2LMdRsp
      IfVeSMSuHMI2L_StMd{4..9}_Rsp: nonqueued-sender-com-spec=data-element=HMI2LMdRsp/Val, provided-interface=HMI2LMdRsp
      IfVeSMSuHMI2R_StMd1_Rsp: nonqueued-sender-com-spec=data-element=HMI2RMdRsp/Val, provided-interface=HMI2RMdRsp
      IfVeSMSuHMI2R_StMd{10..19}_Rsp: nonqueued-sender-com-spec=data-element=HMI2RMdRsp/Val, provided-interface=HMI2RMdRsp
      IfVeSMSuHMI2R_StMd2_Rsp: nonqueued-sender-com-spec=data-element=HMI2RMdRsp/Val, provided-interface=HMI2RMdRsp
      IfVeSMSuHMI2R_StMd{20..29}_Rsp: nonqueued-sender-com-spec=data-element=HMI2RMdRsp/Val, provided-interface=HMI2RMdRsp
      IfVeSMSuHMI2R_StMd3_Rsp: nonqueued-sender-com-spec=data-element=HMI2RMdRsp/Val, provided-interface=HMI2RMdRsp
      IfVeSMSuHMI2R_StMd{30..32}_Rsp: nonqueued-sender-com-spec=data-element=HMI2RMdRsp/Val, provided-interface=HMI2RMdRsp
      IfVeSMSuHMI2R_StMd{4..9}_Rsp: nonqueued-sender-com-spec=data-element=HMI2RMdRsp/Val, provided-interface=HMI2RMdRsp
      IfVeSMSuSRSCrt_MdSw1_Stat: nonqueued-sender-com-spec=data-element=SRSCrtMdStat_67_2/Val, provided-interface=SRSCrtMdStat_67_2
      IfVeSMSuSRSCrt_MdSw10_Stat: nonqueued-sender-com-spec=data-element=SRSCrtMdStat_67_2/Val, provided-interface=SRSCrtMdStat_67_2
      IfVeSMSuSRSCrt_MdSw{2..9}_Stat: nonqueued-sender-com-spec=data-element=SRSCrtMdStat_67_2/Val, provided-interface=SRSCrtMdStat_67_2
      IfVeSMSuSRSCrtMdIndTyp_67_2: nonqueued-sender-com-spec=data-element=SRSCrtMdIndTyp_67_2/Val, provided-interface=SRSCrtMdIndTyp_67_2
      IfVeSMSuSRSMdSlctSwIndTyp_67_2: nonqueued-sender-com-spec{data-element=SRSMdSlctSwIndTyp_67_2/Val, init-value=1}, provided-interface=SRSMdSlctSwIndTyp_67_2
      IfVeSMSuStPassCmprtMd_Md1_CrtStat: nonqueued-sender-com-spec=data-element=StPassCmprtMdCrtMdStat/Val, provided-interface=StPassCmprtMdCrtMdStat
      IfVeSMSuStPassCmprtMd_Md{10..19}_CrtStat: nonqueued-sender-com-spec=data-element=StPassCmprtMdCrtMdStat/Val, provided-interface=StPassCmprtMdCrtMdStat
      IfVeSMSuStPassCmprtMd_Md2_CrtStat: nonqueued-sender-com-spec=data-element=StPassCmprtMdCrtMdStat/Val, provided-interface=StPassCmprtMdCrtMdStat
      IfVeSMSuStPassCmprtMd_Md{20..29}_CrtStat: nonqueued-sender-com-spec=data-element=StPassCmprtMdCrtMdStat/Val, provided-interface=StPassCmprtMdCrtMdStat
      IfVeSMSuStPassCmprtMd_Md3_CrtStat: nonqueued-sender-com-spec=data-element=StPassCmprtMdCrtMdStat/Val, provided-interface=StPassCmprtMdCrtMdStat
      IfVeSMSuStPassCmprtMd_Md{30..32}_CrtStat: nonqueued-sender-com-spec=data-element=StPassCmprtMdCrtMdStat/Val, provided-interface=StPassCmprtMdCrtMdStat
      IfVeSMSuStPassCmprtMd_Md{4..9}_CrtStat: nonqueued-sender-com-spec=data-element=StPassCmprtMdCrtMdStat/Val, provided-interface=StPassCmprtMdCrtMdStat
      IfVeSMSuStPassCmprtMd{10..19}RclRspStat: nonqueued-sender-com-spec=data-element=MdRclRspStat/Val, provided-interface=MdRclRspStat
      IfVeSMSuStPassCmprtMd1RclRspStat: nonqueued-sender-com-spec=data-element=MdRclRspStat/Val, provided-interface=MdRclRspStat
      IfVeSMSuStPassCmprtMd{20..29}RclRspStat: nonqueued-sender-com-spec=data-element=MdRclRspStat/Val, provided-interface=MdRclRspStat
      IfVeSMSuStPassCmprtMd2RclRspStat: nonqueued-sender-com-spec=data-element=MdRclRspStat/Val, provided-interface=MdRclRspStat
      IfVeSMSuStPassCmprtMd{30..32}RclRspStat: nonqueued-sender-com-spec=data-element=MdRclRspStat/Val, provided-interface=MdRclRspStat
      IfVeSMSuStPassCmprtMd{3..9}RclRspStat: nonqueued-sender-com-spec=data-element=MdRclRspStat/Val, provided-interface=MdRclRspStat
      IfVeSMSuStPassCmprtMdCrtMdStat: nonqueued-sender-com-spec{data-element=StPassCmprtMdCrtMdStat/Val, init-value=0}, provided-interface=StPassCmprtMdCrtMdStat
      IfVeSMSuStPassCmprtMdHMIDisCmd: nonqueued-sender-com-spec=data-element=StPassCmprtMdHMIDisCmdSrv/Val, provided-interface=StPassCmprtMdHMIDisCmdSrv
      IfVeSMSuStSrv_StMd1_Rsp: nonqueued-sender-com-spec=data-element=StSrvMdRsp/Val, provided-interface=StSrvMdRsp
      IfVeSMSuStSrv_StMd{10..19}_Rsp: nonqueued-sender-com-spec=data-element=StSrvMdRsp/Val, provided-interface=StSrvMdRsp
      IfVeSMSuStSrv_StMd2_Rsp: nonqueued-sender-com-spec=data-element=StSrvMdRsp/Val, provided-interface=StSrvMdRsp
      IfVeSMSuStSrv_StMd{20..29}_Rsp: nonqueued-sender-com-spec=data-element=StSrvMdRsp/Val, provided-interface=StSrvMdRsp
      IfVeSMSuStSrv_StMd3_Rsp: nonqueued-sender-com-spec=data-element=StSrvMdRsp/Val, provided-interface=StSrvMdRsp
      IfVeSMSuStSrv_StMd{30..32}_Rsp: nonqueued-sender-com-spec=data-element=StSrvMdRsp/Val, provided-interface=StSrvMdRsp
      IfVeSMSuStSrv_StMd{4..9}_Rsp: nonqueued-sender-com-spec=data-element=StSrvMdRsp/Val, provided-interface=StSrvMdRsp
      ModeRsp: server-com-spec{operation=ModeRsp/Cal, queue-length=1}, provided-interface=ModeRsp
      ModeSrcTpLt: nonqueued-sender-com-spec{data-element=ModeSrcTp/Val, init-value=0}, provided-interface=ModeSrcTp
      oModeState: nonqueued-sender-com-spec=data-element=ModeState/Val, provided-interface=ModeState
      SRSMdSlctSwStat_67_2: nonqueued-sender-com-spec{data-element=SRSMdSlctSwStat_67_2/Val, init-value=0}, provided-interface=SRSMdSlctSwStat_67_2
      SRSMode: nonqueued-sender-com-spec=data-element=SRSCurMode/Val, provided-interface=SRSCurMode
    19 x require port:
      IfVeSMSuChmMgrStat: nonqueued-receiver-com-spec{data-element=IfVeSMSuChmMgrStat/Val, filter=data-filter-type=ALWAYS}, required-interface=IfVeSMSuChmMgrStat
      IfVeSMSuSRSMdSlctSwIndTyp_67_2_In: nonqueued-receiver-com-spec{data-element=SRSMdSlctSwIndTyp_67_2/Val, filter=data-filter-type=ALWAYS, init-value=1}, required-interface=SRSMdSlctSwIndTyp_67_2
      IsStBsy32Bit: nonqueued-receiver-com-spec{data-element=IsStBsy32Bit/Val, filter=data-filter-type=ALWAYS, init-value=0}, required-interface=IsStBsy32Bit
      KeSMSbMdChime2Enable: parameter-require-com-spec{init-value=0, parameter=MdChime2Enable/Val}, required-interface=MdChime2Enable
      KeSMSbSRSPosNumConfig: parameter-require-com-spec{init-value=4, parameter=SRSPosNumConfig/Val}, required-interface=SRSPosNumConfig
      KeSMSuChmReqDurnTm: parameter-require-com-spec{init-value=200, parameter=KeSMSuChmReqDurnTm/Val}, required-interface=KeSMSuChmReqDurnTm
      KeSMSuChmReqIntlTm: parameter-require-com-spec{init-value=50, parameter=KeSMSuChmReqIntlTm/Val}, required-interface=KeSMSuChmReqIntlTm
      KeSMSuMdNums: parameter-require-com-spec{init-value=26, parameter=KeSMSuMdNums/Val}, required-interface=KeSMSuMdNums
      KeSMSuRspStatHldTm: parameter-require-com-spec{init-value=100, parameter=KeSMSuRspStatHldTm/Val}, required-interface=KeSMSuRspStatHldTm
      KeSMSuSRSMdSlctSwDurnTm: parameter-require-com-spec{init-value=20, parameter=KeSMSuSRSMdSlctSwDurnTm/Val}, required-interface=KeSMSuSRSMdSlctSwDurnTm
      MdXX_QuitArray: nonqueued-receiver-com-spec{data-element=MdXX_QuitArray/Val, filter=data-filter-type=ALWAYS, init-value=32 x 0}, required-interface=MdXX_QuitArray
      MdXX_SrcReqTpArray: nonqueued-receiver-com-spec{data-element=MdXX_SrcReqTpArray/Val, filter=data-filter-type=ALWAYS}, required-interface=MdXX_SrcReqTpArray
      MdXXIsTargetPosAlready: nonqueued-receiver-com-spec{data-element=IsTargetPos32Bit/Val, filter=data-filter-type=ALWAYS, init-value=0}, required-interface=IsTargetPos32Bit
      MdXXIsTargetPosZone: nonqueued-receiver-com-spec{data-element=IsTargetPos32Bit/Val, filter=data-filter-type=ALWAYS, init-value=0}, required-interface=IsTargetPos32Bit
      modestate32: nonqueued-receiver-com-spec{data-element=modestate32/Val, filter=data-filter-type=ALWAYS, init-value=0}, required-interface=modestate32
      PosArray: nonqueued-receiver-com-spec{data-element=PosArray/Val, filter=data-filter-type=ALWAYS, init-value=11 x 0}, required-interface=PosArray
      PwrMdChked: nonqueued-receiver-com-spec{data-element=PowerMode/Val, filter=data-filter-type=ALWAYS}, required-interface=PowerMode
      SRSconvertArray: parameter-require-com-spec{init-value=[0, 1, 5, 8, 2, 9, 10, 11, 6, 7, 3, 12, 4, 13, 14, 15, 16, 17, 18, 19, 20, 21, 22, 23, 24, 25, 26, 27, 28, 29, 30, 31], parameter=SRSconvertArray/Val}, required-interface=SRSconvertArray
      SRSMdSlctSwStat_67_2_In: nonqueued-receiver-com-spec{data-element=SRSMdSlctSwStat_67_2/Val, filter=data-filter-type=ALWAYS, init-value=0}, required-interface=SRSMdSlctSwStat_67_2
    9 x component:
      CHM2Ctrl: type=CHM2Ctrl
      MdXX_RspOutComm: type=MdXX_RspOutComm
      MdXX_RspToNetWork: type=MdXX_RspToNetWork
      MdXX_Status: type=MdXX_Status
      MdXX_StatusToNetWork: type=MdXX_StatusToNetWork
      ModeRspCaller: type=ModeRspCaller
      SRSModeState: type=SRSModeState
      SRSSwIndCtrl: type=SRSSwIndCtrl
      StPassCmprtMdHMIDisCmd: type=StPassCmprtMdHMIDisCmd
    connect CHM2Ctrl.CHM2Ctrl -> ModeRspCaller.CHM2Ctrl
    connect MdXX_RspOutComm.MdXX_RspOutComm -> MdXX_RspToNetWork.MdXX_RspOutComm
    connect MdXX_RspOutComm.MdXX_SrcReqTpOutComm -> MdXX_RspToNetWork.MdXX_SrcReqTp
    connect MdXX_RspOutComm.MdXX_RspOutComm -> MdXX_Status.MdXX_RspOutComm
    connect MdXX_RspOutComm.MdXX_RspOutCommCalc -> ModeRspCaller.MdXX_RspOutCommCalc
    connect MdXX_RspOutComm.MdXX_SrcReqTpOutComm -> SRSModeState.MdXX_SrcReqTp
    connect MdXX_RspToNetWork.MdXX_RspToNetWork -> ModeRspCaller.MdXX_RspToNetWork
    connect MdXX_RspToNetWork.IfVeSMStPassCmprtMd_RfCtrl_Sw_RclRspStat -> SRSSwIndCtrl.IfVeSMStPassCmprtMd_RfCtrl_Sw_RclRspStat
    connect MdXX_Status.MdXX_Stat -> MdXX_StatusToNetWork.MdXX_Stat
    connect MdXX_Status.MdXX_Status -> ModeRspCaller.MdXX_Status
    connect MdXX_StatusToNetWork.MdXX_StatusToNetWork -> ModeRspCaller.MdXX_StatusToNetWork
    connect MdXX_StatusToNetWork.IfVeSMSuSRSCrt_MdSw1_Stat -> SRSSwIndCtrl.IfVeSMSuSRSCrt_MdSw1_Stat_In
    connect MdXX_StatusToNetWork.IfVeSMSuSRSCrt_MdSw10_Stat -> SRSSwIndCtrl.IfVeSMSuSRSCrt_MdSw10_Stat_In
    connect MdXX_StatusToNetWork.IfVeSMSuSRSCrt_MdSw{2..9}_Stat -> SRSSwIndCtrl.IfVeSMSuSRSCrt_MdSw{2..9}_Stat_In
    connect MdXX_StatusToNetWork.IfVeSMSuSRSCrtMdIndTyp_67_2 -> SRSSwIndCtrl.IfVeSMSuSRSCrtMdIndTyp_67_2_In
    connect SRSModeState.SRSModeState -> ModeRspCaller.SRSModeState
    connect SRSSwIndCtrl.SRSSwIndCtrl -> ModeRspCaller.SRSSwIndCtrl
    connect StPassCmprtMdHMIDisCmd.StPassCmprtMdHMIDisCmdCalc -> ModeRspCaller.StPassCmprtMdHMIDisCmdCalc
    delegate CHM2Ctrl.IfVeSMSeStPassCmprtMdNoti2ChmEvntStat <-> outer port ModeRsp/IfVeSMSeStPassCmprtMdNoti2ChmEvntStat
    delegate MdXX_RspToNetWork.IfVeSMStPassCmprtMd_RfCtrl_Sw_RclRspStat <-> outer port ModeRsp/IfVeSMStPassCmprtMd_RfCtrl_Sw_RclRspStat
    delegate CHM2Ctrl.IfVeSMSuChmMgrStat <-> outer port ModeRsp/IfVeSMSuChmMgrStat
    delegate MdXX_RspToNetWork.IfVeSMSuHMI2L_StMd1_Rsp <-> outer port ModeRsp/IfVeSMSuHMI2L_StMd1_Rsp
    delegate MdXX_RspToNetWork.IfVeSMSuHMI2L_StMd{10..19}_Rsp <-> outer port ModeRsp/IfVeSMSuHMI2L_StMd{10..19}_Rsp
    delegate MdXX_RspToNetWork.IfVeSMSuHMI2L_StMd2_Rsp <-> outer port ModeRsp/IfVeSMSuHMI2L_StMd2_Rsp
    delegate MdXX_RspToNetWork.IfVeSMSuHMI2L_StMd{20..29}_Rsp <-> outer port ModeRsp/IfVeSMSuHMI2L_StMd{20..29}_Rsp
    delegate MdXX_RspToNetWork.IfVeSMSuHMI2L_StMd3_Rsp <-> outer port ModeRsp/IfVeSMSuHMI2L_StMd3_Rsp
    delegate MdXX_RspToNetWork.IfVeSMSuHMI2L_StMd{30..32}_Rsp <-> outer port ModeRsp/IfVeSMSuHMI2L_StMd{30..32}_Rsp
    delegate MdXX_RspToNetWork.IfVeSMSuHMI2L_StMd{4..9}_Rsp <-> outer port ModeRsp/IfVeSMSuHMI2L_StMd{4..9}_Rsp
    delegate MdXX_RspToNetWork.IfVeSMSuHMI2R_StMd1_Rsp <-> outer port ModeRsp/IfVeSMSuHMI2R_StMd1_Rsp
    delegate MdXX_RspToNetWork.IfVeSMSuHMI2R_StMd{10..19}_Rsp <-> outer port ModeRsp/IfVeSMSuHMI2R_StMd{10..19}_Rsp
    delegate MdXX_RspToNetWork.IfVeSMSuHMI2R_StMd2_Rsp <-> outer port ModeRsp/IfVeSMSuHMI2R_StMd2_Rsp
    delegate MdXX_RspToNetWork.IfVeSMSuHMI2R_StMd{20..29}_Rsp <-> outer port ModeRsp/IfVeSMSuHMI2R_StMd{20..29}_Rsp
    delegate MdXX_RspToNetWork.IfVeSMSuHMI2R_StMd3_Rsp <-> outer port ModeRsp/IfVeSMSuHMI2R_StMd3_Rsp
    delegate MdXX_RspToNetWork.IfVeSMSuHMI2R_StMd{30..32}_Rsp <-> outer port ModeRsp/IfVeSMSuHMI2R_StMd{30..32}_Rsp
    delegate MdXX_RspToNetWork.IfVeSMSuHMI2R_StMd{4..9}_Rsp <-> outer port ModeRsp/IfVeSMSuHMI2R_StMd{4..9}_Rsp
    delegate SRSSwIndCtrl.IfVeSMSuSRSCrt_MdSw1_Stat <-> outer port ModeRsp/IfVeSMSuSRSCrt_MdSw1_Stat
    delegate SRSSwIndCtrl.IfVeSMSuSRSCrt_MdSw10_Stat <-> outer port ModeRsp/IfVeSMSuSRSCrt_MdSw10_Stat
    delegate SRSSwIndCtrl.IfVeSMSuSRSCrt_MdSw{2..9}_Stat <-> outer port ModeRsp/IfVeSMSuSRSCrt_MdSw{2..9}_Stat
    delegate SRSSwIndCtrl.IfVeSMSuSRSCrtMdIndTyp_67_2 <-> outer port ModeRsp/IfVeSMSuSRSCrtMdIndTyp_67_2
    delegate SRSSwIndCtrl.IfVeSMSuSRSMdSlctSwIndTyp_67_2 <-> outer port ModeRsp/IfVeSMSuSRSMdSlctSwIndTyp_67_2
    delegate SRSSwIndCtrl.IfVeSMSuSRSMdSlctSwIndTyp_67_2_In <-> outer port ModeRsp/IfVeSMSuSRSMdSlctSwIndTyp_67_2_In
    delegate MdXX_StatusToNetWork.IfVeSMSuStPassCmprtMd_Md1_CrtStat <-> outer port ModeRsp/IfVeSMSuStPassCmprtMd_Md1_CrtStat
    delegate MdXX_StatusToNetWork.IfVeSMSuStPassCmprtMd_Md{10..19}_CrtStat <-> outer port ModeRsp/IfVeSMSuStPassCmprtMd_Md{10..19}_CrtStat
    delegate MdXX_StatusToNetWork.IfVeSMSuStPassCmprtMd_Md2_CrtStat <-> outer port ModeRsp/IfVeSMSuStPassCmprtMd_Md2_CrtStat
    delegate MdXX_StatusToNetWork.IfVeSMSuStPassCmprtMd_Md{20..29}_CrtStat <-> outer port ModeRsp/IfVeSMSuStPassCmprtMd_Md{20..29}_CrtStat
    delegate MdXX_StatusToNetWork.IfVeSMSuStPassCmprtMd_Md3_CrtStat <-> outer port ModeRsp/IfVeSMSuStPassCmprtMd_Md3_CrtStat
    delegate MdXX_StatusToNetWork.IfVeSMSuStPassCmprtMd_Md{30..32}_CrtStat <-> outer port ModeRsp/IfVeSMSuStPassCmprtMd_Md{30..32}_CrtStat
    delegate MdXX_StatusToNetWork.IfVeSMSuStPassCmprtMd_Md{4..9}_CrtStat <-> outer port ModeRsp/IfVeSMSuStPassCmprtMd_Md{4..9}_CrtStat
    delegate MdXX_RspToNetWork.IfVeSMSuStPassCmprtMd{10..19}RclRspStat <-> outer port ModeRsp/IfVeSMSuStPassCmprtMd{10..19}RclRspStat
    delegate MdXX_RspToNetWork.IfVeSMSuStPassCmprtMd1RclRspStat <-> outer port ModeRsp/IfVeSMSuStPassCmprtMd1RclRspStat
    delegate MdXX_RspToNetWork.IfVeSMSuStPassCmprtMd{20..29}RclRspStat <-> outer port ModeRsp/IfVeSMSuStPassCmprtMd{20..29}RclRspStat
    delegate MdXX_RspToNetWork.IfVeSMSuStPassCmprtMd2RclRspStat <-> outer port ModeRsp/IfVeSMSuStPassCmprtMd2RclRspStat
    delegate MdXX_RspToNetWork.IfVeSMSuStPassCmprtMd{30..32}RclRspStat <-> outer port ModeRsp/IfVeSMSuStPassCmprtMd{30..32}RclRspStat
    delegate MdXX_RspToNetWork.IfVeSMSuStPassCmprtMd{3..9}RclRspStat <-> outer port ModeRsp/IfVeSMSuStPassCmprtMd{3..9}RclRspStat
    delegate MdXX_StatusToNetWork.IfVeSMSuStPassCmprtMdCrtMdStat <-> outer port ModeRsp/IfVeSMSuStPassCmprtMdCrtMdStat
    delegate StPassCmprtMdHMIDisCmd.IfVeSMSuStPassCmprtMdHMIDisCmd <-> outer port ModeRsp/IfVeSMSuStPassCmprtMdHMIDisCmd
    delegate MdXX_RspToNetWork.IfVeSMSuStSrv_StMd1_Rsp <-> outer port ModeRsp/IfVeSMSuStSrv_StMd1_Rsp
    delegate MdXX_RspToNetWork.IfVeSMSuStSrv_StMd{10..19}_Rsp <-> outer port ModeRsp/IfVeSMSuStSrv_StMd{10..19}_Rsp
    delegate MdXX_RspToNetWork.IfVeSMSuStSrv_StMd2_Rsp <-> outer port ModeRsp/IfVeSMSuStSrv_StMd2_Rsp
    delegate MdXX_RspToNetWork.IfVeSMSuStSrv_StMd{20..29}_Rsp <-> outer port ModeRsp/IfVeSMSuStSrv_StMd{20..29}_Rsp
    delegate MdXX_RspToNetWork.IfVeSMSuStSrv_StMd3_Rsp <-> outer port ModeRsp/IfVeSMSuStSrv_StMd3_Rsp
    delegate MdXX_RspToNetWork.IfVeSMSuStSrv_StMd{30..32}_Rsp <-> outer port ModeRsp/IfVeSMSuStSrv_StMd{30..32}_Rsp
    delegate MdXX_RspToNetWork.IfVeSMSuStSrv_StMd{4..9}_Rsp <-> outer port ModeRsp/IfVeSMSuStSrv_StMd{4..9}_Rsp
    delegate MdXX_Status.IsStBsy32Bit <-> outer port ModeRsp/IsStBsy32Bit
    delegate CHM2Ctrl.KeSMSbMdChime2Enable <-> outer port ModeRsp/KeSMSbMdChime2Enable
    delegate MdXX_StatusToNetWork.KeSMSbSRSPosNumConfig <-> outer port ModeRsp/KeSMSbSRSPosNumConfig
    delegate CHM2Ctrl.KeSMSuChmReqDurnTm <-> outer port ModeRsp/KeSMSuChmReqDurnTm
    delegate CHM2Ctrl.KeSMSuChmReqIntlTm <-> outer port ModeRsp/KeSMSuChmReqIntlTm
    delegate SRSModeState.KeSMSuMdNums <-> outer port ModeRsp/KeSMSuMdNums
    delegate MdXX_RspOutComm.KeSMSuRspStatHldTm <-> outer port ModeRsp/KeSMSuRspStatHldTm
    delegate SRSSwIndCtrl.KeSMSuSRSMdSlctSwDurnTm <-> outer port ModeRsp/KeSMSuSRSMdSlctSwDurnTm
    delegate MdXX_RspOutComm.MdXX_QuitArray <-> outer port ModeRsp/MdXX_QuitArray
    delegate MdXX_RspOutComm.MdXX_SrcReqTpArray <-> outer port ModeRsp/MdXX_SrcReqTpArray
    delegate MdXX_RspOutComm.MdXXIsTargetPosAlready <-> outer port ModeRsp/MdXXIsTargetPosAlready
    delegate MdXX_Status.MdXXIsTargetPosZone <-> outer port ModeRsp/MdXXIsTargetPosZone
    delegate ModeRspCaller.ModeRsp <-> outer port ModeRsp/ModeRsp
    delegate SRSModeState.ModeSrcTpLt <-> outer port ModeRsp/ModeSrcTpLt
    delegate MdXX_RspOutComm.modestate32 <-> outer port ModeRsp/modestate32
    delegate CHM2Ctrl.modestate32 <-> outer port ModeRsp/modestate32
    delegate StPassCmprtMdHMIDisCmd.modestate32 <-> outer port ModeRsp/modestate32
    delegate SRSModeState.modestate32 <-> outer port ModeRsp/modestate32
    delegate SRSModeState.oModeState <-> outer port ModeRsp/oModeState
    delegate MdXX_StatusToNetWork.PosArray <-> outer port ModeRsp/PosArray
    delegate StPassCmprtMdHMIDisCmd.PwrMdChked <-> outer port ModeRsp/PwrMdChked
    delegate SRSModeState.SRSconvertArray <-> outer port ModeRsp/SRSconvertArray
    delegate SRSSwIndCtrl.SRSMdSlctSwStat_67_2 <-> outer port ModeRsp/SRSMdSlctSwStat_67_2
    delegate SRSSwIndCtrl.SRSMdSlctSwStat_67_2_In <-> outer port ModeRsp/SRSMdSlctSwStat_67_2_In
    delegate SRSModeState.SRSMode <-> outer port ModeRsp/SRSMode
  composition sw component type ModeStatCtrl
    5 x provide port:
      IsStBsy32Bit: nonqueued-sender-com-spec{data-element=IsStBsy32Bit/Val, init-value=0}, provided-interface=IsStBsy32Bit
      MdXX_QuitArray: nonqueued-sender-com-spec{data-element=MdXX_QuitArray/Val, init-value=32 x 0}, provided-interface=MdXX_QuitArray
      MdXX_SrcReqTpArray: provided-interface=MdXX_SrcReqTpArray
      modestate32: nonqueued-sender-com-spec{data-element=modestate32/Val, init-value=0}, provided-interface=modestate32
      ModeStateCtrl: server-com-spec{operation=ModeStateCtrl/Cal, queue-length=1}, provided-interface=ModeStateCtrl
    121 x require port:
      acsEntyMdReq: nonqueued-receiver-com-spec{data-element=MdReq/Val, filter=data-filter-type=ALWAYS, init-value=0}, required-interface=MdReq
      acsEntyMdSrcTp: nonqueued-receiver-com-spec{data-element=ModeSrcTp/Val, filter=data-filter-type=ALWAYS, init-value=0}, required-interface=ModeSrcTp
      acsExtMdReq: nonqueued-receiver-com-spec{data-element=MdReq/Val, filter=data-filter-type=ALWAYS, init-value=0}, required-interface=MdReq
      acsExtMdSrcTp: nonqueued-receiver-com-spec{data-element=ModeSrcTp/Val, filter=data-filter-type=ALWAYS, init-value=0}, required-interface=ModeSrcTp
      AllLugMdReq: nonqueued-receiver-com-spec{data-element=MdReq/Val, filter=data-filter-type=ALWAYS, init-value=0}, required-interface=MdReq
      AllLugSrcReqTp: nonqueued-receiver-com-spec{data-element=ModeSrcTp/Val, filter=data-filter-type=ALWAYS, init-value=0}, required-interface=ModeSrcTp
      AllVipMdReq: nonqueued-receiver-com-spec{data-element=MdReq/Val, filter=data-filter-type=ALWAYS, init-value=0}, required-interface=MdReq
      AllVipSrcReqTp: nonqueued-receiver-com-spec{data-element=ModeSrcTp/Val, filter=data-filter-type=ALWAYS, init-value=0}, required-interface=ModeSrcTp
      CommCond: nonqueued-receiver-com-spec{data-element=CommCond/Val, filter=data-filter-type=ALWAYS, init-value=0}, required-interface=CommCond
      CommExitCond: nonqueued-receiver-com-spec{data-element=CommExitCond/Val, filter=data-filter-type=ALWAYS, init-value=0}, required-interface=CommExitCond
      CommExitCondwithSpeed: nonqueued-receiver-com-spec{data-element=CommExitCondwithSpeed/Val, filter=data-filter-type=ALWAYS, init-value=0}, required-interface=CommExitCondwithSpeed
      EZE4sLMdSrcTp: nonqueued-receiver-com-spec{data-element=ModeSrcTp/Val, filter=data-filter-type=ALWAYS, init-value=0}, required-interface=ModeSrcTp
      EZE4sLtMdReq: nonqueued-receiver-com-spec{data-element=AnyModeAjust/Val, filter=data-filter-type=ALWAYS, init-value=0}, required-interface=AnyModeAjust
      EZE4sRMdSrcTp: nonqueued-receiver-com-spec{data-element=ModeSrcTp/Val, filter=data-filter-type=ALWAYS, init-value=0}, required-interface=ModeSrcTp
      EZE4sRtMdReq: nonqueued-receiver-com-spec{data-element=AnyModeAjust/Val, filter=data-filter-type=ALWAYS, init-value=0}, required-interface=AnyModeAjust
      EZQ4sLMdSrcTp: nonqueued-receiver-com-spec{data-element=ModeSrcTp/Val, filter=data-filter-type=ALWAYS, init-value=0}, required-interface=ModeSrcTp
      EZQ4sLtMdReq: nonqueued-receiver-com-spec{data-element=AnyModeAjust/Val, filter=data-filter-type=ALWAYS, init-value=0}, required-interface=AnyModeAjust
      EZQ4sRMdSrcTp: nonqueued-receiver-com-spec{data-element=ModeSrcTp/Val, filter=data-filter-type=ALWAYS, init-value=0}, required-interface=ModeSrcTp
      EZQ4sRtMdReq: nonqueued-receiver-com-spec{data-element=AnyModeAjust/Val, filter=data-filter-type=ALWAYS, init-value=0}, required-interface=AnyModeAjust
      IfVeSMSuSecRwLtStFrwdBkwdPos: nonqueued-receiver-com-spec{data-element=IfVeSMSuSecRwLtStFrwdBkwdPos/Val, filter=data-filter-type=ALWAYS, init-value=0}, required-interface=IfVeSMSuSecRwLtStFrwdBkwdPos
      IfVeSMSuSecRwRtStFrwdBkwdPos: nonqueued-receiver-com-spec{data-element=PercPos/Val, filter=data-filter-type=ALWAYS, init-value=0}, required-interface=PercPos
      IntimacyRtMdReq: nonqueued-receiver-com-spec{data-element=AnyModeAjust/Val, filter=data-filter-type=ALWAYS, init-value=0}, required-interface=AnyModeAjust
      IntimacyRtMdSrcTp: nonqueued-receiver-com-spec{data-element=ModeSrcTp/Val, filter=data-filter-type=ALWAYS, init-value=0}, required-interface=ModeSrcTp
      INTMMdReq: nonqueued-receiver-com-spec{data-element=MdReq/Val, filter=data-filter-type=ALWAYS, init-value=0}, required-interface=MdReq
      INTMSrcReqTp: nonqueued-receiver-com-spec{data-element=ModeSrcTp/Val, filter=data-filter-type=ALWAYS, init-value=0}, required-interface=ModeSrcTp
      KeSMSAutoEZEFwdBkwdPosEna: parameter-require-com-spec{init-value=0, parameter=KeSMSAutoEZEFwdBkwdPosEna/Val}, required-interface=KeSMSAutoEZEFwdBkwdPosEna
      KeSMSuButtonLongPressedThrshldTm: parameter-require-com-spec{init-value=100, parameter=KeSMSuButtonLongPressedThrshldTm/Val}, required-interface=KeSMSuButtonLongPressedThrshldTm
      KeSMSuMdNum4s: parameter-require-com-spec{init-value=16, parameter=KeSMSuMdNum4s/Val}, required-interface=KeSMSuMdNum4s
      KeSMSuMdNum6s7s: parameter-require-com-spec{init-value=14, parameter=KeSMSuMdNum6s7s/Val}, required-interface=KeSMSuMdNum6s7s
      KeSMSuMdNums: parameter-require-com-spec{init-value=26, parameter=KeSMSuMdNums/Val}, required-interface=KeSMSuMdNums
      LfFamlyReq: nonqueued-receiver-com-spec{data-element=MdReq/Val, filter=data-filter-type=ALWAYS, init-value=0}, required-interface=MdReq
      LfFamlySrcReqTp: nonqueued-receiver-com-spec{data-element=ModeSrcTp/Val, filter=data-filter-type=ALWAYS, init-value=0}, required-interface=ModeSrcTp
      LfLyMdReq: nonqueued-receiver-com-spec{data-element=MdReq/Val, filter=data-filter-type=ALWAYS, init-value=0}, required-interface=MdReq
      LfLySrcReqTp: nonqueued-receiver-com-spec{data-element=ModeSrcTp/Val, filter=data-filter-type=ALWAYS, init-value=0}, required-interface=ModeSrcTp
      LgrstCloseLtMdReq: nonqueued-receiver-com-spec{data-element=AnyModeAjust/Val, filter=data-filter-type=ALWAYS, init-value=0}, required-interface=AnyModeAjust
      LgrstCloseLtSrcReqTp: nonqueued-receiver-com-spec{data-element=ModeSrcTp/Val, filter=data-filter-type=ALWAYS, init-value=0}, required-interface=ModeSrcTp
      LgrstCloseRtMdReq: nonqueued-receiver-com-spec{data-element=AnyModeAjust/Val, filter=data-filter-type=ALWAYS, init-value=0}, required-interface=AnyModeAjust
      LgrstCloseRtSrcReqTp: nonqueued-receiver-com-spec{data-element=ModeSrcTp/Val, filter=data-filter-type=ALWAYS, init-value=0}, required-interface=ModeSrcTp
      LgrstOpenLtMdReq: nonqueued-receiver-com-spec{data-element=AnyModeAjust/Val, filter=data-filter-type=ALWAYS, init-value=0}, required-interface=AnyModeAjust
      LgrstOpenLtSrcReqTp: nonqueued-receiver-com-spec{data-element=ModeSrcTp/Val, filter=data-filter-type=ALWAYS, init-value=0}, required-interface=ModeSrcTp
      LgrstOpenRtMdReq: nonqueued-receiver-com-spec{data-element=AnyModeAjust/Val, filter=data-filter-type=ALWAYS, init-value=0}, required-interface=AnyModeAjust
      LgrstOpenRtSrcReqTp: nonqueued-receiver-com-spec{data-element=ModeSrcTp/Val, filter=data-filter-type=ALWAYS, init-value=0}, required-interface=ModeSrcTp
      LtLugMdReq: nonqueued-receiver-com-spec{data-element=MdReq/Val, filter=data-filter-type=ALWAYS, init-value=0}, required-interface=MdReq
      LtLugSrcReqTp: nonqueued-receiver-com-spec{data-element=ModeSrcTp/Val, filter=data-filter-type=ALWAYS, init-value=0}, required-interface=ModeSrcTp
      LtRcvyMdReq: nonqueued-receiver-com-spec{data-element=MdReq/Val, filter=data-filter-type=ALWAYS, init-value=0}, required-interface=MdReq
      LtRcvySrcReqTp: nonqueued-receiver-com-spec{data-element=ModeSrcTp/Val, filter=data-filter-type=ALWAYS, init-value=0}, required-interface=ModeSrcTp
      LtVipMdReq: nonqueued-receiver-com-spec{data-element=MdReq/Val, filter=data-filter-type=ALWAYS, init-value=0}, required-interface=MdReq
      LtVipSrcReqTp: nonqueued-receiver-com-spec{data-element=ModeSrcTp/Val, filter=data-filter-type=ALWAYS, init-value=0}, required-interface=ModeSrcTp
      LugMdLtAvl: nonqueued-receiver-com-spec{data-element=ModeAdjustAvailable/Val, filter=data-filter-type=ALWAYS, init-value=0}, required-interface=ModeAdjustAvailable
      LugMdRtAvl: nonqueued-receiver-com-spec{data-element=ModeAdjustAvailable/Val, filter=data-filter-type=ALWAYS, init-value=0}, required-interface=ModeAdjustAvailable
      MdSWIntSrc_R: nonqueued-receiver-com-spec{data-element=MdSWIntSrc_R/Val, filter=data-filter-type=ALWAYS, init-value=0}, required-interface=MdSWIntSrc_R
      MdXX_MdDoneArray: nonqueued-receiver-com-spec{data-element=MdXX_MdDoneArray/Val, filter=data-filter-type=ALWAYS, init-value=32 x 0}, required-interface=MdXX_MdDoneArray
      RtFamlyMdReq: nonqueued-receiver-com-spec{data-element=MdReq/Val, filter=data-filter-type=ALWAYS, init-value=0}, required-interface=MdReq
      RtFamlySrcReqTp: nonqueued-receiver-com-spec{data-element=ModeSrcTp/Val, filter=data-filter-type=ALWAYS, init-value=0}, required-interface=ModeSrcTp
      RtLugMdReq: nonqueued-receiver-com-spec{data-element=MdReq/Val, filter=data-filter-type=ALWAYS, init-value=0}, required-interface=MdReq
      RtLugSrcReqTp: nonqueued-receiver-com-spec{data-element=ModeSrcTp/Val, filter=data-filter-type=ALWAYS, init-value=0}, required-interface=ModeSrcTp
      RtLyMdReq: nonqueued-receiver-com-spec{data-element=MdReq/Val, filter=data-filter-type=ALWAYS, init-value=0}, required-interface=MdReq
      RtLySrcReqTp: nonqueued-receiver-com-spec{data-element=ModeSrcTp/Val, filter=data-filter-type=ALWAYS, init-value=0}, required-interface=ModeSrcTp
      RtRcvyMdReq: nonqueued-receiver-com-spec{data-element=MdReq/Val, filter=data-filter-type=ALWAYS, init-value=0}, required-interface=MdReq
      RtRcvySrcReqTp: nonqueued-receiver-com-spec{data-element=ModeSrcTp/Val, filter=data-filter-type=ALWAYS, init-value=0}, required-interface=ModeSrcTp
      RtVipMdReq: nonqueued-receiver-com-spec{data-element=MdReq/Val, filter=data-filter-type=ALWAYS, init-value=0}, required-interface=MdReq
      RtVipSrcReqTp: nonqueued-receiver-com-spec{data-element=ModeSrcTp/Val, filter=data-filter-type=ALWAYS, init-value=0}, required-interface=ModeSrcTp
      SoftIntAcsEnty: nonqueued-receiver-com-spec{data-element=MdReq/Val, filter=data-filter-type=ALWAYS, init-value=0}, required-interface=MdReq
      SoftIntAcsExt: nonqueued-receiver-com-spec{data-element=MdReq/Val, filter=data-filter-type=ALWAYS, init-value=0}, required-interface=MdReq
      SoftIntAllLug: nonqueued-receiver-com-spec{data-element=MdReq/Val, filter=data-filter-type=ALWAYS, init-value=0}, required-interface=MdReq
      SoftIntAllVip: nonqueued-receiver-com-spec{data-element=MdReq/Val, filter=data-filter-type=ALWAYS, init-value=0}, required-interface=MdReq
      SoftIntEZE4sL: nonqueued-receiver-com-spec{data-element=IntEnable/Val, filter=data-filter-type=ALWAYS, init-value=0}, required-interface=IntEnable
      SoftIntEZE4sR: nonqueued-receiver-com-spec{data-element=IntEnable/Val, filter=data-filter-type=ALWAYS, init-value=0}, required-interface=IntEnable
      SoftIntEZQ4sL: nonqueued-receiver-com-spec{data-element=IntEnable/Val, filter=data-filter-type=ALWAYS, init-value=0}, required-interface=IntEnable
      SoftIntEZQ4sR: nonqueued-receiver-com-spec{data-element=IntEnable/Val, filter=data-filter-type=ALWAYS, init-value=0}, required-interface=IntEnable
      SoftIntIntimacyRt: nonqueued-receiver-com-spec{data-element=IntEnable/Val, filter=data-filter-type=ALWAYS, init-value=0}, required-interface=IntEnable
      SoftIntINTM: nonqueued-receiver-com-spec{data-element=MdReq/Val, filter=data-filter-type=ALWAYS, init-value=0}, required-interface=MdReq
      SoftIntLfFamly: nonqueued-receiver-com-spec{data-element=MdReq/Val, filter=data-filter-type=ALWAYS, init-value=0}, required-interface=MdReq
      SoftIntLfLug: nonqueued-receiver-com-spec{data-element=MdReq/Val, filter=data-filter-type=ALWAYS, init-value=0}, required-interface=MdReq
      SoftIntLfLy: nonqueued-receiver-com-spec{data-element=MdReq/Val, filter=data-filter-type=ALWAYS, init-value=0}, required-interface=MdReq
      SoftIntLfRcvy: nonqueued-receiver-com-spec{data-element=MdReq/Val, filter=data-filter-type=ALWAYS, init-value=0}, required-interface=MdReq
      SoftIntLfVip: nonqueued-receiver-com-spec{data-element=MdReq/Val, filter=data-filter-type=ALWAYS, init-value=0}, required-interface=MdReq
      SoftIntLgrstCloseLt: nonqueued-receiver-com-spec{data-element=IntEnable/Val, filter=data-filter-type=ALWAYS, init-value=0}, required-interface=IntEnable
      SoftIntLgrstCloseRt: nonqueued-receiver-com-spec{data-element=IntEnable/Val, filter=data-filter-type=ALWAYS, init-value=0}, required-interface=IntEnable
      SoftIntLgrstOpenLt: nonqueued-receiver-com-spec{data-element=IntEnable/Val, filter=data-filter-type=ALWAYS, init-value=0}, required-interface=IntEnable
      SoftIntLgrstOpenRt: nonqueued-receiver-com-spec{data-element=IntEnable/Val, filter=data-filter-type=ALWAYS, init-value=0}, required-interface=IntEnable
      SoftIntRtFamly: nonqueued-receiver-com-spec{data-element=MdReq/Val, filter=data-filter-type=ALWAYS, init-value=0}, required-interface=MdReq
      SoftIntRtLug: nonqueued-receiver-com-spec{data-element=MdReq/Val, filter=data-filter-type=ALWAYS, init-value=0}, required-interface=MdReq
      SoftIntRtLy: nonqueued-receiver-com-spec{data-element=MdReq/Val, filter=data-filter-type=ALWAYS, init-value=0}, required-interface=MdReq
      SoftIntRtRcvy: nonqueued-receiver-com-spec{data-element=MdReq/Val, filter=data-filter-type=ALWAYS, init-value=0}, required-interface=MdReq
      SoftIntRtVip: nonqueued-receiver-com-spec{data-element=MdReq/Val, filter=data-filter-type=ALWAYS, init-value=0}, required-interface=MdReq
      SoftIntWelcomeBkwd: nonqueued-receiver-com-spec{data-element=IntEnable/Val, filter=data-filter-type=ALWAYS, init-value=0}, required-interface=IntEnable
      SoftIntWelcomeFwd: nonqueued-receiver-com-spec{data-element=IntEnable/Val, filter=data-filter-type=ALWAYS, init-value=0}, required-interface=IntEnable
      StNumFlg: required-interface=StNumFlg
        required-com-specs:
          data-element=Is4s, filter=data-filter-type=ALWAYS, init-value=0
          data-element=Is6s, filter=data-filter-type=ALWAYS, init-value=0
          data-element=Is6s7s, filter=data-filter-type=ALWAYS, init-value=0
          data-element=Is7s, filter=data-filter-type=ALWAYS, init-value=0
      SwIntAcsEnty: nonqueued-receiver-com-spec{data-element=MdReq/Val, filter=data-filter-type=ALWAYS, init-value=0}, required-interface=MdReq
      SwIntAcsExt: nonqueued-receiver-com-spec{data-element=MdReq/Val, filter=data-filter-type=ALWAYS, init-value=0}, required-interface=MdReq
      SwIntAllLug: nonqueued-receiver-com-spec{data-element=MdReq/Val, filter=data-filter-type=ALWAYS, init-value=0}, required-interface=MdReq
      SwIntAllVip: nonqueued-receiver-com-spec{data-element=IntEnable/Val, filter=data-filter-type=ALWAYS, init-value=0}, required-interface=IntEnable
      SwIntEZE4sL: nonqueued-receiver-com-spec{data-element=IntEnable/Val, filter=data-filter-type=ALWAYS, init-value=0}, required-interface=IntEnable
      SwIntEZE4sR: nonqueued-receiver-com-spec{data-element=IntEnable/Val, filter=data-filter-type=ALWAYS, init-value=0}, required-interface=IntEnable
      SwIntEZQ4sL: nonqueued-receiver-com-spec{data-element=IntEnable/Val, filter=data-filter-type=ALWAYS, init-value=0}, required-interface=IntEnable
      SwIntEZQ4sR: nonqueued-receiver-com-spec{data-element=IntEnable/Val, filter=data-filter-type=ALWAYS, init-value=0}, required-interface=IntEnable
      SwIntIntimacyRt: nonqueued-receiver-com-spec{data-element=IntEnable/Val, filter=data-filter-type=ALWAYS, init-value=0}, required-interface=IntEnable
      SwIntINTM: nonqueued-receiver-com-spec{data-element=MdReq/Val, filter=data-filter-type=ALWAYS, init-value=0}, required-interface=MdReq
      SwIntLfFamly: nonqueued-receiver-com-spec{data-element=MdReq/Val, filter=data-filter-type=ALWAYS, init-value=0}, required-interface=MdReq
      SwIntLfLug: nonqueued-receiver-com-spec{data-element=MdReq/Val, filter=data-filter-type=ALWAYS, init-value=0}, required-interface=MdReq
      SwIntLfLy: nonqueued-receiver-com-spec{data-element=MdReq/Val, filter=data-filter-type=ALWAYS, init-value=0}, required-interface=MdReq
      SwIntLfRcvy: nonqueued-receiver-com-spec{data-element=MdReq/Val, filter=data-filter-type=ALWAYS, init-value=0}, required-interface=MdReq
      SwIntLfVip: nonqueued-receiver-com-spec{data-element=MdReq/Val, filter=data-filter-type=ALWAYS, init-value=0}, required-interface=MdReq
      SwIntLgrstCloseLt: nonqueued-receiver-com-spec{data-element=IntEnable/Val, filter=data-filter-type=ALWAYS, init-value=0}, required-interface=IntEnable
      SwIntLgrstCloseRt: nonqueued-receiver-com-spec{data-element=IntEnable/Val, filter=data-filter-type=ALWAYS, init-value=0}, required-interface=IntEnable
      SwIntLgrstOpenLt: nonqueued-receiver-com-spec{data-element=IntEnable/Val, filter=data-filter-type=ALWAYS, init-value=0}, required-interface=IntEnable
      SwIntLgrstOpenRt: nonqueued-receiver-com-spec{data-element=IntEnable/Val, filter=data-filter-type=ALWAYS, init-value=0}, required-interface=IntEnable
      SwIntRtFamly: nonqueued-receiver-com-spec{data-element=MdReq/Val, filter=data-filter-type=ALWAYS, init-value=0}, required-interface=MdReq
      SwIntRtLug: nonqueued-receiver-com-spec{data-element=MdReq/Val, filter=data-filter-type=ALWAYS, init-value=0}, required-interface=MdReq
      SwIntRtLy: nonqueued-receiver-com-spec{data-element=MdReq/Val, filter=data-filter-type=ALWAYS, init-value=0}, required-interface=MdReq
      SwIntRtRcvy: nonqueued-receiver-com-spec{data-element=MdReq/Val, filter=data-filter-type=ALWAYS, init-value=0}, required-interface=MdReq
      SwIntRtVip: nonqueued-receiver-com-spec{data-element=MdReq/Val, filter=data-filter-type=ALWAYS, init-value=0}, required-interface=MdReq
      SwIntWelcomeBkwd: nonqueued-receiver-com-spec{data-element=IntEnable/Val, filter=data-filter-type=ALWAYS, init-value=0}, required-interface=IntEnable
      SwIntWelcomeFwd: nonqueued-receiver-com-spec{data-element=IntEnable/Val, filter=data-filter-type=ALWAYS, init-value=0}, required-interface=IntEnable
      VipMdLtAvl: nonqueued-receiver-com-spec{data-element=ModeAdjustAvailable/Val, filter=data-filter-type=ALWAYS, init-value=0}, required-interface=ModeAdjustAvailable
      VipMdRtAvl: nonqueued-receiver-com-spec{data-element=ModeAdjustAvailable/Val, filter=data-filter-type=ALWAYS, init-value=0}, required-interface=ModeAdjustAvailable
      WelcomeBkwdMdReq: nonqueued-receiver-com-spec{data-element=AnyModeAjust/Val, filter=data-filter-type=ALWAYS, init-value=0}, required-interface=AnyModeAjust
      WelcomeBkwdMdSrcTp: nonqueued-receiver-com-spec{data-element=ModeSrcTp/Val, filter=data-filter-type=ALWAYS, init-value=0}, required-interface=ModeSrcTp
      WelcomeFwdMdReq: nonqueued-receiver-com-spec{data-element=AnyModeAjust/Val, filter=data-filter-type=ALWAYS, init-value=0}, required-interface=AnyModeAjust
      WelcomeFwdMdSrcTp: nonqueued-receiver-com-spec{data-element=ModeSrcTp/Val, filter=data-filter-type=ALWAYS, init-value=0}, required-interface=ModeSrcTp
    7 x component:
      MdEnCtrlAndBsyChk: type=MdEnCtrlAndBsyChk
      MdSWReqChk: type=MdSWReqChk
      MdXX_QuitChk: type=MdXX_QuitChk
      MdXX_QuitReason: type=MdXX_QuitReason
      MdXXArray: type=MdXXArray
      ModeStateCtrlCaller: type=ModeStateCtrlCaller
      StateOnOffChk: type=StateOnOffChk
    connect MdEnCtrlAndBsyChk.MdEnAndBsyChk -> ModeStateCtrlCaller.MdEnAndBsyChk
    connect MdSWReqChk.ChkBsyBitArray -> MdEnCtrlAndBsyChk.ChkBsyBitArray
    connect MdSWReqChk.MdReqArray -> MdEnCtrlAndBsyChk.MdReqArray
    connect MdSWReqChk.SetBsyBitArray -> MdEnCtrlAndBsyChk.SetBsyBitArray
    connect MdSWReqChk.SetEnBitArray -> MdEnCtrlAndBsyChk.SetEnBitArray
    connect MdSWReqChk.VeSMSuMdNum -> MdEnCtrlAndBsyChk.VeSMSuMdNum
    connect MdSWReqChk.MdSWReqChk -> ModeStateCtrlCaller.MdSWReqChk
    connect MdXX_QuitChk.MdXX_Quit32bit -> MdEnCtrlAndBsyChk.MdXX_Quit32bit
    connect MdXX_QuitChk.MdXX_QuitChk -> ModeStateCtrlCaller.MdXX_QuitChk
    connect MdXX_QuitReason.MdXX_QuitReason -> MdXX_QuitChk.MdXX_QuitReason
    connect MdXXArray.MdXX_CommExitArray -> MdXX_QuitChk.MdXX_CommExitArray
    connect MdXXArray.MdXX_SoftIntArray -> MdXX_QuitChk.MdXX_SoftIntArray
    connect MdXXArray.MdXX_SWIntArray -> MdXX_QuitChk.MdXX_SWIntArray
    connect MdXXArray.MdXXArray -> ModeStateCtrlCaller.MdXXArray
    connect StateOnOffChk.stateonoffchk -> ModeStateCtrlCaller.stateonoffchk
    delegate MdSWReqChk.acsEntyMdReq <-> outer port ModeStatCtrl/acsEntyMdReq
    delegate MdXXArray.acsEntyMdSrcTp <-> outer port ModeStatCtrl/acsEntyMdSrcTp
    delegate MdSWReqChk.acsExtMdReq <-> outer port ModeStatCtrl/acsExtMdReq
    delegate MdXXArray.acsExtMdSrcTp <-> outer port ModeStatCtrl/acsExtMdSrcTp
    delegate MdSWReqChk.AllLugMdReq <-> outer port ModeStatCtrl/AllLugMdReq
    delegate MdXXArray.AllLugSrcReqTp <-> outer port ModeStatCtrl/AllLugSrcReqTp
    delegate MdSWReqChk.AllVipMdReq <-> outer port ModeStatCtrl/AllVipMdReq
    delegate MdXXArray.AllVipSrcReqTp <-> outer port ModeStatCtrl/AllVipSrcReqTp
    delegate StateOnOffChk.CommCond <-> outer port ModeStatCtrl/CommCond
    delegate MdXXArray.CommExitCond <-> outer port ModeStatCtrl/CommExitCond
    delegate MdXXArray.CommExitCondwithSpeed <-> outer port ModeStatCtrl/CommExitCondwithSpeed
    delegate MdXXArray.EZE4sLMdSrcTp <-> outer port ModeStatCtrl/EZE4sLMdSrcTp
    delegate MdSWReqChk.EZE4sLtMdReq <-> outer port ModeStatCtrl/EZE4sLtMdReq
    delegate MdXXArray.EZE4sRMdSrcTp <-> outer port ModeStatCtrl/EZE4sRMdSrcTp
    delegate MdSWReqChk.EZE4sRtMdReq <-> outer port ModeStatCtrl/EZE4sRtMdReq
    delegate MdXXArray.EZQ4sLMdSrcTp <-> outer port ModeStatCtrl/EZQ4sLMdSrcTp
    delegate MdSWReqChk.EZQ4sLtMdReq <-> outer port ModeStatCtrl/EZQ4sLtMdReq
    delegate MdXXArray.EZQ4sRMdSrcTp <-> outer port ModeStatCtrl/EZQ4sRMdSrcTp
    delegate MdSWReqChk.EZQ4sRtMdReq <-> outer port ModeStatCtrl/EZQ4sRtMdReq
    delegate MdSWReqChk.IfVeSMSuSecRwLtStFrwdBkwdPos <-> outer port ModeStatCtrl/IfVeSMSuSecRwLtStFrwdBkwdPos
    delegate MdSWReqChk.IfVeSMSuSecRwRtStFrwdBkwdPos <-> outer port ModeStatCtrl/IfVeSMSuSecRwRtStFrwdBkwdPos
    delegate MdSWReqChk.IntimacyRtMdReq <-> outer port ModeStatCtrl/IntimacyRtMdReq
    delegate MdXXArray.IntimacyRtMdSrcTp <-> outer port ModeStatCtrl/IntimacyRtMdSrcTp
    delegate MdSWReqChk.INTMMdReq <-> outer port ModeStatCtrl/INTMMdReq
    delegate MdXXArray.INTMSrcReqTp <-> outer port ModeStatCtrl/INTMSrcReqTp
    delegate MdEnCtrlAndBsyChk.IsStBsy32Bit <-> outer port ModeStatCtrl/IsStBsy32Bit
    delegate MdSWReqChk.KeSMSAutoEZEFwdBkwdPosEna <-> outer port ModeStatCtrl/KeSMSAutoEZEFwdBkwdPosEna
    delegate MdSWReqChk.KeSMSuButtonLongPressedThrshldTm <-> outer port ModeStatCtrl/KeSMSuButtonLongPressedThrshldTm
    delegate MdSWReqChk.KeSMSuMdNum4s <-> outer port ModeStatCtrl/KeSMSuMdNum4s
    delegate MdSWReqChk.KeSMSuMdNum6s7s <-> outer port ModeStatCtrl/KeSMSuMdNum6s7s
    delegate MdXX_QuitChk.KeSMSuMdNums <-> outer port ModeStatCtrl/KeSMSuMdNums
    delegate MdSWReqChk.LfFamlyReq <-> outer port ModeStatCtrl/LfFamlyReq
    delegate MdXXArray.LfFamlySrcReqTp <-> outer port ModeStatCtrl/LfFamlySrcReqTp
    delegate MdSWReqChk.LfLyMdReq <-> outer port ModeStatCtrl/LfLyMdReq
    delegate MdXXArray.LfLySrcReqTp <-> outer port ModeStatCtrl/LfLySrcReqTp
    delegate MdSWReqChk.LgrstCloseLtMdReq <-> outer port ModeStatCtrl/LgrstCloseLtMdReq
    delegate MdXXArray.LgrstCloseLtSrcReqTp <-> outer port ModeStatCtrl/LgrstCloseLtSrcReqTp
    delegate MdSWReqChk.LgrstCloseRtMdReq <-> outer port ModeStatCtrl/LgrstCloseRtMdReq
    delegate MdXXArray.LgrstCloseRtSrcReqTp <-> outer port ModeStatCtrl/LgrstCloseRtSrcReqTp
    delegate MdSWReqChk.LgrstOpenLtMdReq <-> outer port ModeStatCtrl/LgrstOpenLtMdReq
    delegate MdXXArray.LgrstOpenLtSrcReqTp <-> outer port ModeStatCtrl/LgrstOpenLtSrcReqTp
    delegate MdSWReqChk.LgrstOpenRtMdReq <-> outer port ModeStatCtrl/LgrstOpenRtMdReq
    delegate MdXXArray.LgrstOpenRtSrcReqTp <-> outer port ModeStatCtrl/LgrstOpenRtSrcReqTp
    delegate MdSWReqChk.LtLugMdReq <-> outer port ModeStatCtrl/LtLugMdReq
    delegate MdXXArray.LtLugSrcReqTp <-> outer port ModeStatCtrl/LtLugSrcReqTp
    delegate MdSWReqChk.LtRcvyMdReq <-> outer port ModeStatCtrl/LtRcvyMdReq
    delegate MdXXArray.LtRcvySrcReqTp <-> outer port ModeStatCtrl/LtRcvySrcReqTp
    delegate MdSWReqChk.LtVipMdReq <-> outer port ModeStatCtrl/LtVipMdReq
    delegate MdXXArray.LtVipSrcReqTp <-> outer port ModeStatCtrl/LtVipSrcReqTp
    delegate MdSWReqChk.LugMdLtAvl <-> outer port ModeStatCtrl/LugMdLtAvl
    delegate MdSWReqChk.LugMdRtAvl <-> outer port ModeStatCtrl/LugMdRtAvl
    delegate MdSWReqChk.MdSWIntSrc_R <-> outer port ModeStatCtrl/MdSWIntSrc_R
    delegate MdXX_QuitChk.MdXX_MdDoneArray <-> outer port ModeStatCtrl/MdXX_MdDoneArray
    delegate MdXX_QuitChk.MdXX_QuitArray <-> outer port ModeStatCtrl/MdXX_QuitArray
    delegate MdXXArray.MdXX_SrcReqTpArray <-> outer port ModeStatCtrl/MdXX_SrcReqTpArray
    delegate MdEnCtrlAndBsyChk.modestate32 <-> outer port ModeStatCtrl/modestate32
    delegate ModeStateCtrlCaller.ModeStateCtrl <-> outer port ModeStatCtrl/ModeStateCtrl
    delegate MdSWReqChk.RtFamlyMdReq <-> outer port ModeStatCtrl/RtFamlyMdReq
    delegate MdXXArray.RtFamlySrcReqTp <-> outer port ModeStatCtrl/RtFamlySrcReqTp
    delegate MdSWReqChk.RtLugMdReq <-> outer port ModeStatCtrl/RtLugMdReq
    delegate MdXXArray.RtLugSrcReqTp <-> outer port ModeStatCtrl/RtLugSrcReqTp
    delegate MdSWReqChk.RtLyMdReq <-> outer port ModeStatCtrl/RtLyMdReq
    delegate MdXXArray.RtLySrcReqTp <-> outer port ModeStatCtrl/RtLySrcReqTp
    delegate MdSWReqChk.RtRcvyMdReq <-> outer port ModeStatCtrl/RtRcvyMdReq
    delegate MdXXArray.RtRcvySrcReqTp <-> outer port ModeStatCtrl/RtRcvySrcReqTp
    delegate MdSWReqChk.RtVipMdReq <-> outer port ModeStatCtrl/RtVipMdReq
    delegate MdXXArray.RtVipSrcReqTp <-> outer port ModeStatCtrl/RtVipSrcReqTp
    delegate MdXXArray.SoftIntAcsEnty <-> outer port ModeStatCtrl/SoftIntAcsEnty
    delegate MdXXArray.SoftIntAcsExt <-> outer port ModeStatCtrl/SoftIntAcsExt
    delegate MdXXArray.SoftIntAllLug <-> outer port ModeStatCtrl/SoftIntAllLug
    delegate MdXXArray.SoftIntAllVip <-> outer port ModeStatCtrl/SoftIntAllVip
    delegate MdXXArray.SoftIntEZE4sL <-> outer port ModeStatCtrl/SoftIntEZE4sL
    delegate MdXXArray.SoftIntEZE4sR <-> outer port ModeStatCtrl/SoftIntEZE4sR
    delegate MdXXArray.SoftIntEZQ4sL <-> outer port ModeStatCtrl/SoftIntEZQ4sL
    delegate MdXXArray.SoftIntEZQ4sR <-> outer port ModeStatCtrl/SoftIntEZQ4sR
    delegate MdXXArray.SoftIntIntimacyRt <-> outer port ModeStatCtrl/SoftIntIntimacyRt
    delegate MdXXArray.SoftIntINTM <-> outer port ModeStatCtrl/SoftIntINTM
    delegate MdXXArray.SoftIntLfFamly <-> outer port ModeStatCtrl/SoftIntLfFamly
    delegate MdXXArray.SoftIntLfLug <-> outer port ModeStatCtrl/SoftIntLfLug
    delegate MdXXArray.SoftIntLfLy <-> outer port ModeStatCtrl/SoftIntLfLy
    delegate MdXXArray.SoftIntLfRcvy <-> outer port ModeStatCtrl/SoftIntLfRcvy
    delegate MdXXArray.SoftIntLfVip <-> outer port ModeStatCtrl/SoftIntLfVip
    delegate MdXXArray.SoftIntLgrstCloseLt <-> outer port ModeStatCtrl/SoftIntLgrstCloseLt
    delegate MdXXArray.SoftIntLgrstCloseRt <-> outer port ModeStatCtrl/SoftIntLgrstCloseRt
    delegate MdXXArray.SoftIntLgrstOpenLt <-> outer port ModeStatCtrl/SoftIntLgrstOpenLt
    delegate MdXXArray.SoftIntLgrstOpenRt <-> outer port ModeStatCtrl/SoftIntLgrstOpenRt
    delegate MdXXArray.SoftIntRtFamly <-> outer port ModeStatCtrl/SoftIntRtFamly
    delegate MdXXArray.SoftIntRtLug <-> outer port ModeStatCtrl/SoftIntRtLug
    delegate MdXXArray.SoftIntRtLy <-> outer port ModeStatCtrl/SoftIntRtLy
    delegate MdXXArray.SoftIntRtRcvy <-> outer port ModeStatCtrl/SoftIntRtRcvy
    delegate MdXXArray.SoftIntRtVip <-> outer port ModeStatCtrl/SoftIntRtVip
    delegate MdXXArray.SoftIntWelcomeBkwd <-> outer port ModeStatCtrl/SoftIntWelcomeBkwd
    delegate MdXXArray.SoftIntWelcomeFwd <-> outer port ModeStatCtrl/SoftIntWelcomeFwd
    delegate MdEnCtrlAndBsyChk.StNumFlg <-> outer port ModeStatCtrl/StNumFlg
    delegate MdSWReqChk.StNumFlg <-> outer port ModeStatCtrl/StNumFlg
    delegate MdSWReqChk.SwIntAcsEnty <-> outer port ModeStatCtrl/SwIntAcsEnty
    delegate MdXXArray.SwIntAcsEnty <-> outer port ModeStatCtrl/SwIntAcsEnty
    delegate MdSWReqChk.SwIntAcsExt <-> outer port ModeStatCtrl/SwIntAcsExt
    delegate MdXXArray.SwIntAcsExt <-> outer port ModeStatCtrl/SwIntAcsExt
    delegate MdSWReqChk.SwIntAllLug <-> outer port ModeStatCtrl/SwIntAllLug
    delegate MdXXArray.SwIntAllLug <-> outer port ModeStatCtrl/SwIntAllLug
    delegate MdXXArray.SwIntAllVip <-> outer port ModeStatCtrl/SwIntAllVip
    delegate MdXXArray.SwIntEZE4sL <-> outer port ModeStatCtrl/SwIntEZE4sL
    delegate MdXXArray.SwIntEZE4sR <-> outer port ModeStatCtrl/SwIntEZE4sR
    delegate MdXXArray.SwIntEZQ4sL <-> outer port ModeStatCtrl/SwIntEZQ4sL
    delegate MdXXArray.SwIntEZQ4sR <-> outer port ModeStatCtrl/SwIntEZQ4sR
    delegate MdXXArray.SwIntIntimacyRt <-> outer port ModeStatCtrl/SwIntIntimacyRt
    delegate MdXXArray.SwIntINTM <-> outer port ModeStatCtrl/SwIntINTM
    delegate MdXXArray.SwIntLfFamly <-> outer port ModeStatCtrl/SwIntLfFamly
    delegate MdXXArray.SwIntLfLug <-> outer port ModeStatCtrl/SwIntLfLug
    delegate MdXXArray.SwIntLfLy <-> outer port ModeStatCtrl/SwIntLfLy
    delegate MdSWReqChk.SwIntLfRcvy <-> outer port ModeStatCtrl/SwIntLfRcvy
    delegate MdXXArray.SwIntLfRcvy <-> outer port ModeStatCtrl/SwIntLfRcvy
    delegate MdSWReqChk.SwIntLfVip <-> outer port ModeStatCtrl/SwIntLfVip
    delegate MdXXArray.SwIntLfVip <-> outer port ModeStatCtrl/SwIntLfVip
    delegate MdXXArray.SwIntLgrstCloseLt <-> outer port ModeStatCtrl/SwIntLgrstCloseLt
    delegate MdXXArray.SwIntLgrstCloseRt <-> outer port ModeStatCtrl/SwIntLgrstCloseRt
    delegate MdXXArray.SwIntLgrstOpenLt <-> outer port ModeStatCtrl/SwIntLgrstOpenLt
    delegate MdXXArray.SwIntLgrstOpenRt <-> outer port ModeStatCtrl/SwIntLgrstOpenRt
    delegate MdXXArray.SwIntRtFamly <-> outer port ModeStatCtrl/SwIntRtFamly
    delegate MdXXArray.SwIntRtLug <-> outer port ModeStatCtrl/SwIntRtLug
    delegate MdXXArray.SwIntRtLy <-> outer port ModeStatCtrl/SwIntRtLy
    delegate MdSWReqChk.SwIntRtRcvy <-> outer port ModeStatCtrl/SwIntRtRcvy
    delegate MdXXArray.SwIntRtRcvy <-> outer port ModeStatCtrl/SwIntRtRcvy
    delegate MdSWReqChk.SwIntRtVip <-> outer port ModeStatCtrl/SwIntRtVip
    delegate MdXXArray.SwIntRtVip <-> outer port ModeStatCtrl/SwIntRtVip
    delegate MdXXArray.SwIntWelcomeBkwd <-> outer port ModeStatCtrl/SwIntWelcomeBkwd
    delegate MdXXArray.SwIntWelcomeFwd <-> outer port ModeStatCtrl/SwIntWelcomeFwd
    delegate MdSWReqChk.VipMdLtAvl <-> outer port ModeStatCtrl/VipMdLtAvl
    delegate MdSWReqChk.VipMdRtAvl <-> outer port ModeStatCtrl/VipMdRtAvl
    delegate MdSWReqChk.WelcomeBkwdMdReq <-> outer port ModeStatCtrl/WelcomeBkwdMdReq
    delegate MdXXArray.WelcomeBkwdMdSrcTp <-> outer port ModeStatCtrl/WelcomeBkwdMdSrcTp
    delegate MdSWReqChk.WelcomeFwdMdReq <-> outer port ModeStatCtrl/WelcomeFwdMdReq
    delegate MdXXArray.WelcomeFwdMdSrcTp <-> outer port ModeStatCtrl/WelcomeFwdMdSrcTp
  26 x swc implementation:
    CHM2ActiveReqChk_Implementation: behavior=CHM2ActiveReqChk_InternalBehavior
      code-descriptors:
        code Default: artifact-descriptors=autosar-engineering-object={short-label=Default, category=SWSRC}
    CHM2ActiveSubStateCtrl_Implementation: behavior=CHM2ActiveSubStateCtrl_InternalBehavior
      code-descriptors:
        code Default: artifact-descriptors=autosar-engineering-object={short-label=Default, category=SWSRC}
    CHM2Ctrl_Caller_Implementation: behavior=CHM2Ctrl_Caller_InternalBehavior
      code-descriptors:
        code Default: artifact-descriptors=autosar-engineering-object={short-label=Default, category=SWSRC}
    CHM2StateCtrl_Implementation: behavior=CHM2StateCtrl_InternalBehavior
      code-descriptors:
        code Default: artifact-descriptors=autosar-engineering-object={short-label=Default, category=SWSRC}
    IsStBsy32BitCalc_Implementation: behavior=IsStBsy32BitCalc_InternalBehavior
      code-descriptors:
        code Default: artifact-descriptors=autosar-engineering-object={short-label=Default, category=SWSRC}
    MdBsyClear4s_Implementation: behavior=MdBsyClear4s_InternalBehavior
      code-descriptors:
        code Default: artifact-descriptors=autosar-engineering-object={short-label=Default, category=SWSRC}
    MdBsyClear6s7s_Implementation: behavior=MdBsyClear6s7s_InternalBehavior
      code-descriptors:
        code Default: artifact-descriptors=autosar-engineering-object={short-label=Default, category=SWSRC}
    MdEnAndBsyChk_Caller_Implementation: behavior=MdEnAndBsyChk_Caller_InternalBehavior
      code-descriptors:
        code Default: artifact-descriptors=autosar-engineering-object={short-label=Default, category=SWSRC}
    MdEnChk_Implementation: behavior=MdEnChk_InternalBehavior
      code-descriptors:
        code Default: artifact-descriptors=autosar-engineering-object={short-label=Default, category=SWSRC}
    MdEnClear_Implementation: behavior=MdEnClear_InternalBehavior
      code-descriptors:
        code Default: artifact-descriptors=autosar-engineering-object={short-label=Default, category=SWSRC}
    MdSWReqChk_Implementation: behavior=MdSWReqChk_InternalBehavior
      code-descriptors:
        code Default: artifact-descriptors=autosar-engineering-object={short-label=Default, category=SWSRC}
    MdXX_QuitChk_Implementation: behavior=MdXX_QuitChk_InternalBehavior
      code-descriptors:
        code Default: artifact-descriptors=autosar-engineering-object={short-label=Default, category=SWSRC}
    MdXX_QuitReason_Implementation: behavior=MdXX_QuitReason_InternalBehavior
      code-descriptors:
        code Default: artifact-descriptors=autosar-engineering-object={short-label=Default, category=SWSRC}
    MdXX_RspOutComm_Implementation: behavior=MdXX_RspOutComm_InternalBehavior
      code-descriptors:
        code Default: artifact-descriptors=autosar-engineering-object={short-label=Default, category=SWSRC}
    MdXX_RspToNetWork_Implementation: behavior=MdXX_RspToNetWork_InternalBehavior
      code-descriptors:
        code Default: artifact-descriptors=autosar-engineering-object={short-label=Default, category=SWSRC}
    MdXX_Status_Implementation: behavior=MdXX_Status_InternalBehavior
      code-descriptors:
        code Default: artifact-descriptors=autosar-engineering-object={short-label=Default, category=SWSRC}
    MdXX_StatusToNetWork_Implementation: behavior=MdXX_StatusToNetWork_InternalBehavior
      code-descriptors:
        code Default: artifact-descriptors=autosar-engineering-object={short-label=Default, category=SWSRC}
    MdXXArray_Implementation: behavior=MdXXArray_InternalBehavior
      code-descriptors:
        code Default: artifact-descriptors=autosar-engineering-object={short-label=Default, category=SWSRC}
    ModeRspCaller_Implementation: behavior=ModeRspCaller_InternalBehavior
      code-descriptors:
        code Default: artifact-descriptors=autosar-engineering-object={short-label=Default, category=SWSRC}
    ModeStatAndRspCaller_Implementation: behavior=ModeStatAndRspCaller_InternalBehavior
      code-descriptors:
        code Default: artifact-descriptors=autosar-engineering-object={short-label=Default, category=SWSRC}
    modestate32Calc_Implementation: behavior=modestate32Calc_InternalBehavior
      code-descriptors:
        code Default: artifact-descriptors=autosar-engineering-object={short-label=Default, category=SWSRC}
    ModeStateCtrlCaller_Implementation: behavior=ModeStateCtrlCaller_InternalBehavior
      code-descriptors:
        code Default: artifact-descriptors=autosar-engineering-object={short-label=Default, category=SWSRC}
    SRSModeState_Implementation: behavior=SRSModeState_InternalBehavior
      code-descriptors:
        code Default: artifact-descriptors=autosar-engineering-object={short-label=Default, category=SWSRC}
    SRSSwIndCtrl_Implementation: behavior=SRSSwIndCtrl_InternalBehavior
      code-descriptors:
        code Default: artifact-descriptors=autosar-engineering-object={short-label=Default, category=SWSRC}
    StateOnOffChk_Implementation: behavior=StateOnOffChk_InternalBehavior
      code-descriptors:
        code Default: artifact-descriptors=autosar-engineering-object={short-label=Default, category=SWSRC}
    StPassCmprtMdHMIDisCmd_Implementation: behavior=StPassCmprtMdHMIDisCmd_InternalBehavior
      code-descriptors:
        code Default: artifact-descriptors=autosar-engineering-object={short-label=Default, category=SWSRC}
package /PATAC/MSM/DataTypes/ImplementationDataTypes
  impl type IntEnable: category=VALUE, base-type=BaseTypes/Boolean, sw-calibration-access=READ-ONLY, type-emitter=RTE
